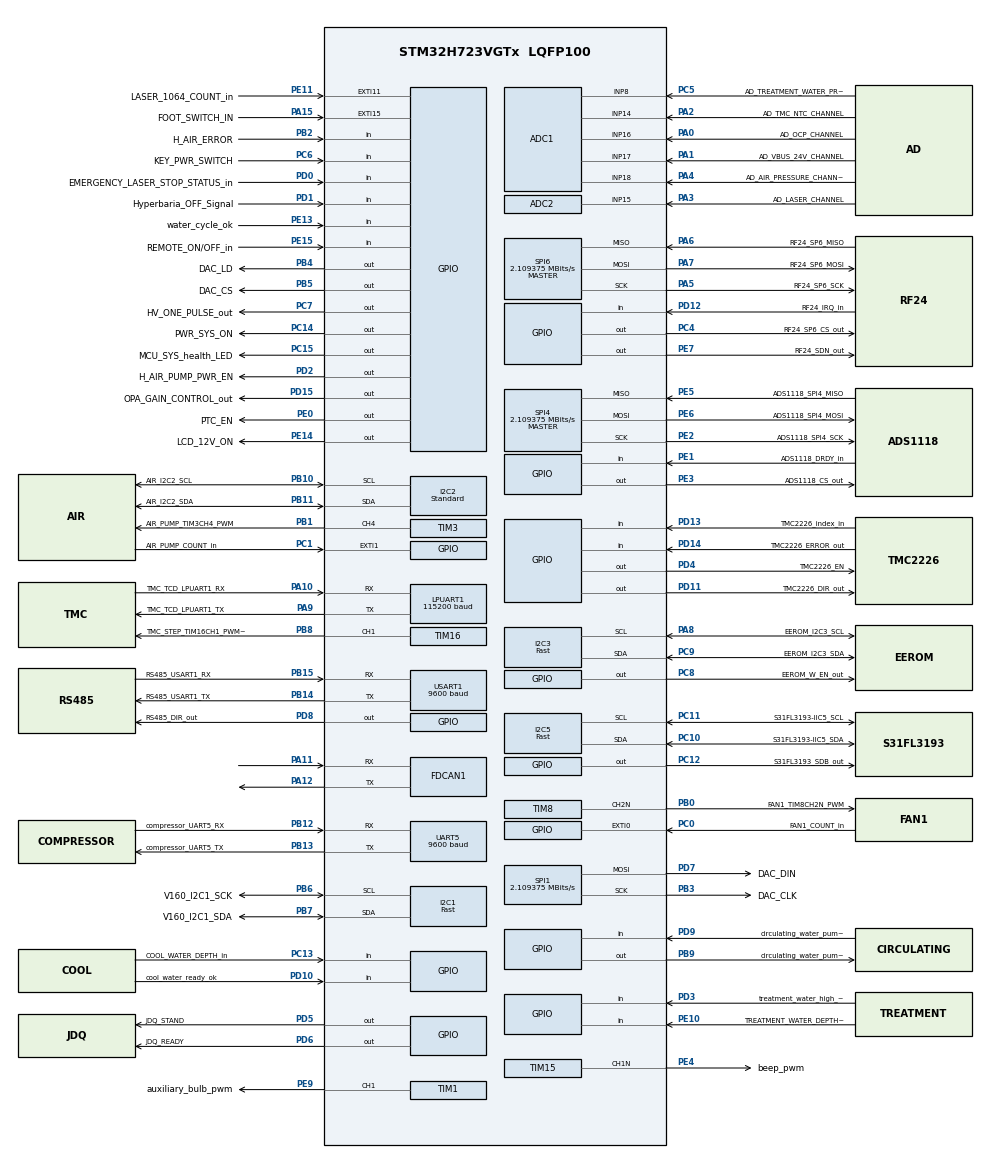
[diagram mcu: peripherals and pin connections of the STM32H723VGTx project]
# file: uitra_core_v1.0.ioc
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ADC1.Channel-11\#ChannelRegularConversion=ADC_CHANNEL_8
ADC1.Channel-12\#ChannelRegularConversion=ADC_CHANNEL_14
ADC1.Channel-13\#ChannelRegularConversion=ADC_CHANNEL_16
ADC1.Channel-14\#ChannelRegularConversion=ADC_CHANNEL_17
ADC1.Channel-16\#ChannelRegularConversion=ADC_CHANNEL_18
ADC1.ClockPrescalerADC3=ADC_CLOCK_ASYNC_DIV4
ADC1.ContinuousConvMode=DISABLE
ADC1.ConversionDataManagement=ADC_CONVERSIONDATA_DMA_CIRCULAR
ADC1.EOCSelection=ADC_EOC_SEQ_CONV
ADC1.EnableInjectedConversion=DISABLE
ADC1.ExternalTrigConv=ADC_EXTERNALTRIG_T6_TRGO
ADC1.LowPowerAutoWait=ENABLE
ADC1.NbrOfConversion=5
ADC1.NbrOfConversionFlag=1
ADC1.OffsetNumber-11\#ChannelRegularConversion=ADC_OFFSET_NONE
ADC1.OffsetNumber-12\#ChannelRegularConversion=ADC_OFFSET_NONE
ADC1.OffsetNumber-13\#ChannelRegularConversion=ADC_OFFSET_NONE
ADC1.OffsetNumber-14\#ChannelRegularConversion=ADC_OFFSET_NONE
ADC1.OffsetNumber-16\#ChannelRegularConversion=ADC_OFFSET_NONE
ADC1.OffsetSignedSaturation-11\#ChannelRegularConversion=DISABLE
ADC1.OffsetSignedSaturation-12\#ChannelRegularConversion=DISABLE
ADC1.OffsetSignedSaturation-13\#ChannelRegularConversion=DISABLE
ADC1.OffsetSignedSaturation-14\#ChannelRegularConversion=DISABLE
ADC1.OffsetSignedSaturation-16\#ChannelRegularConversion=DISABLE
ADC1.Rank-11\#ChannelRegularConversion=1
ADC1.Rank-12\#ChannelRegularConversion=2
ADC1.Rank-13\#ChannelRegularConversion=3
ADC1.Rank-14\#ChannelRegularConversion=4
ADC1.Rank-16\#ChannelRegularConversion=5
ADC1.SamplingTime-11\#ChannelRegularConversion=ADC_SAMPLETIME_64CYCLES_5
ADC1.SamplingTime-12\#ChannelRegularConversion=ADC_SAMPLETIME_64CYCLES_5
ADC1.SamplingTime-13\#ChannelRegularConversion=ADC_SAMPLETIME_64CYCLES_5
ADC1.SamplingTime-14\#ChannelRegularConversion=ADC_SAMPLETIME_64CYCLES_5
ADC1.SamplingTime-16\#ChannelRegularConversion=ADC_SAMPLETIME_64CYCLES_5
ADC1.master=1
ADC2.Channel-0\#ChannelRegularConversion=ADC_CHANNEL_15
ADC2.ClockPrescalerADC3=ADC_CLOCK_ASYNC_DIV4
ADC2.ContinuousConvMode=ENABLE
ADC2.ConversionDataManagement=ADC_CONVERSIONDATA_DMA_ONESHOT
ADC2.EOCSelection=ADC_EOC_SEQ_CONV
ADC2.EnableInjectedConversion=DISABLE
ADC2.EnableRegularConversion=ENABLE
ADC2.ExternalTrigConv=ADC_SOFTWARE_START
ADC2.LowPowerAutoWait=ENABLE
ADC2.NbrOfConversionFlag=1
ADC2.OffsetNumber-0\#ChannelRegularConversion=ADC_OFFSET_NONE
ADC2.OffsetSignedSaturation-0\#ChannelRegularConversion=DISABLE
ADC2.Rank-0\#ChannelRegularConversion=1
ADC2.SamplingTime-0\#ChannelRegularConversion=ADC_SAMPLETIME_64CYCLES_5
CORTEX_M7.CPU_DCache=Enabled
CORTEX_M7.CPU_ICache=Enabled
CORTEX_M7.Enable_S-Cortex_Memory_Protection_Unit_Region1_Settings_S=__NULL
CORTEX_M7.Enable_Spec=MPU_REGION_ENABLE
CORTEX_M7.default_mode_Activation=1
Dma.ADC1.0.Direction=DMA_PERIPH_TO_MEMORY
Dma.ADC1.0.EventEnable=DISABLE
Dma.ADC1.0.FIFOMode=DMA_FIFOMODE_ENABLE
Dma.ADC1.0.FIFOThreshold=DMA_FIFO_THRESHOLD_FULL
Dma.ADC1.0.Instance=DMA1_Stream0
Dma.ADC1.0.MemBurst=DMA_MBURST_SINGLE
Dma.ADC1.0.MemDataAlignment=DMA_MDATAALIGN_HALFWORD
Dma.ADC1.0.MemInc=DMA_MINC_ENABLE
Dma.ADC1.0.Mode=DMA_CIRCULAR
Dma.ADC1.0.PeriphBurst=DMA_PBURST_SINGLE
Dma.ADC1.0.PeriphDataAlignment=DMA_PDATAALIGN_HALFWORD
Dma.ADC1.0.PeriphInc=DMA_PINC_DISABLE
Dma.ADC1.0.Polarity=HAL_DMAMUX_REQ_GEN_RISING
Dma.ADC1.0.Priority=DMA_PRIORITY_LOW
Dma.ADC1.0.RequestNumber=1
Dma.ADC1.0.SignalID=NONE
Dma.ADC1.0.SyncEnable=DISABLE
Dma.ADC1.0.SyncPolarity=HAL_DMAMUX_SYNC_NO_EVENT
Dma.ADC1.0.SyncRequestNumber=1
Dma.ADC1.0.SyncSignalID=NONE
Dma.ADC2.1.Direction=DMA_PERIPH_TO_MEMORY
Dma.ADC2.1.EventEnable=DISABLE
Dma.ADC2.1.FIFOMode=DMA_FIFOMODE_ENABLE
Dma.ADC2.1.FIFOThreshold=DMA_FIFO_THRESHOLD_FULL
Dma.ADC2.1.Instance=DMA2_Stream0
Dma.ADC2.1.MemBurst=DMA_MBURST_SINGLE
Dma.ADC2.1.MemDataAlignment=DMA_MDATAALIGN_HALFWORD
Dma.ADC2.1.MemInc=DMA_MINC_ENABLE
Dma.ADC2.1.Mode=DMA_CIRCULAR
Dma.ADC2.1.PeriphBurst=DMA_PBURST_SINGLE
Dma.ADC2.1.PeriphDataAlignment=DMA_PDATAALIGN_HALFWORD
Dma.ADC2.1.PeriphInc=DMA_PINC_DISABLE
Dma.ADC2.1.Polarity=HAL_DMAMUX_REQ_GEN_RISING
Dma.ADC2.1.Priority=DMA_PRIORITY_LOW
Dma.ADC2.1.RequestNumber=1
Dma.ADC2.1.SignalID=NONE
Dma.ADC2.1.SyncEnable=DISABLE
Dma.ADC2.1.SyncPolarity=HAL_DMAMUX_SYNC_NO_EVENT
Dma.ADC2.1.SyncRequestNumber=1
Dma.ADC2.1.SyncSignalID=NONE
Dma.Request0=ADC1
Dma.Request1=ADC2
FDCAN1.AutoRetransmission=DISABLE
FDCAN1.CalculateBaudRateNominal=125000
FDCAN1.CalculateTimeBitNominal=8000
FDCAN1.CalculateTimeQuantumNominal=400.0
FDCAN1.ClockCalibrationCCU=DISABLE
FDCAN1.DataPrescaler=1
FDCAN1.NominalPrescaler=12
FDCAN1.NominalSyncJumpWidth=1
FDCAN1.NominalTimeSeg1=10
FDCAN1.NominalTimeSeg2=9
FDCAN1.RxBuffersNbr=64
FDCAN1.RxFifo0ElmtSize=FDCAN_DATA_BYTES_8
FDCAN1.RxFifo0ElmtsNbr=64
FDCAN1.RxFifo1ElmtsNbr=0
FDCAN1.StdFiltersNbr=0
FDCAN1.TxFifoQueueElmtsNbr=3
FDCAN1.TxFifoQueueMode=FDCAN_TX_FIFO_OPERATION
FREERTOS.BinarySemaphores01=powerOffBinarySem02,Dynamic,NULL,Depleted;laserPrapareReqSem03,Dynamic,NULL,Depleted;laserCloseSem05,Dynamic,NULL,Depleted;hmiCanBusIdleSem06,Dynamic,NULL,Depleted;jdqHeart100msBinarySem05,Dynamic,NULL,Depleted;aux1SHeartBinarySem06,Dynamic,NULL,Depleted
FREERTOS.Events01=auxStatusEvent01,Static,auxStatusEvent01ControlBlock;laserEvent02,Static,laserEvent02ControlBlock
FREERTOS.Queues01=rgbQueue02,3,uint16_t,0,Dynamic,NULL,NULL;musicQueue03,3,uint16_t,0,Dynamic,NULL,NULL;keyJTMessageQueue01,3,uint16_t,0,Dynamic,NULL,NULL;jdqGwb3200CtrMessageQueue04,3,8,1,Static,jdqGwb3200CtrMessageQueue04Buffer,jdqGwb3200CtrMessageQueue04ControlBlock
FREERTOS.Tasks01=defaultTask,40,312,StartDefaultTask,Default,NULL,Dynamic,NULL,NULL;myTask02,28,312,auxTask02,Default,NULL,Dynamic,NULL,NULL;myTask03,31,160,keyScanTask03,Default,NULL,Dynamic,NULL,NULL;myTask04,30,312,laserWorkTask04,Default,NULL,Dynamic,NULL,NULL;myTask05,29,256,fastAuxTask05,Default,NULL,Dynamic,NULL,NULL;myTask06,29,192,hmiAppTask06,Default,NULL,Dynamic,NULL,NULL;myTask07,29,256,canReceiveTask07,Default,NULL,Dynamic,NULL,NULL;myTask08,31,128,powerOffTask08,Default,NULL,Dynamic,NULL,NULL;myTask09,29,256,laserProhotTask09,Default,NULL,Dynamic,NULL,NULL;myTask10,28,256,ge2117ManageTask10,Default,NULL,Dynamic,NULL,NULL;myTask11,28,128,musicTask11,Default,NULL,Dynamic,NULL,NULL;jdqGWB3200wTask,29,256,jdqGWB3200wTask12,Default,NULL,Dynamic,NULL,NULL
FREERTOS.Timers01=laserWorkTimer01,LaserWorkTimerCallback01,osTimerOnce,Default,NULL,Dynamic,NULL;cleanTimer02,cleanWaterCallback02,osTimerOnce,Default,NULL,Dynamic,NULL;tmcMaxRunTimer03,tmcMaxRunTimesCallback03,osTimerOnce,Default,NULL,Dynamic,NULL;jdqHeart100msTimer04,jdqHeart100msCallback04,osTimerPeriodic,Default,NULL,Dynamic,NULL
FREERTOS.configTOTAL_HEAP_SIZE=32768
FREERTOS.configUSE_IDLE_HOOK=1
I2C1.CustomTiming=Disabled
I2C1.I2C_Fall_Time=50
I2C1.I2C_Rise_Time=50
I2C1.I2C_Speed_Mode=I2C_Fast
I2C1.Timing=0x10A02671
I2C2.CustomTiming=Disabled
I2C2.I2C_Fall_Time=50
I2C2.I2C_Rise_Time=100
I2C2.I2C_Speed_Mode=I2C_Standard
I2C2.Speed=100
I2C2.Timing=0x30B08DB9
I2C3.CustomTiming=Disabled
I2C3.I2C_Fall_Time=10
I2C3.I2C_Rise_Time=100
I2C3.I2C_Speed_Mode=I2C_Fast
I2C3.NoStretchMode=I2C_NOSTRETCH_DISABLE
I2C3.Timing=0x40500E2D
I2C5.I2C_Fall_Time=10
I2C5.I2C_Rise_Time=100
I2C5.I2C_Speed_Mode=I2C_Fast
I2C5.Timing=0x40500E2D
IWDG1.Prescaler=IWDG_PRESCALER_32
IWDG1.Reload=2000
IWDG1.Window=2000
LPUART1.BaudRate=115200
LPUART1.OneBitSampling=UART_ONE_BIT_SAMPLE_ENABLE
Mcu.Family=STM32H7
Mcu.Name=STM32H723VGTx
Mcu.Package=LQFP100
Mcu.UserConstants=adtest,adtest
NVIC.ADC_IRQn=true\:5\:0\:false\:false\:true\:true\:true\:true\:true
NVIC.DMA1_Stream0_IRQn=true\:5\:0\:false\:false\:true\:false\:false\:true\:true
NVIC.DMA2_Stream0_IRQn=true\:5\:0\:false\:false\:true\:false\:false\:true\:true
NVIC.EXTI0_IRQn=true\:5\:0\:false\:false\:true\:true\:true\:true\:true
NVIC.EXTI15_10_IRQn=true\:5\:0\:false\:false\:true\:true\:true\:true\:true
NVIC.EXTI1_IRQn=true\:5\:0\:false\:false\:true\:true\:true\:true\:true
NVIC.LPUART1_IRQn=true\:5\:0\:true\:false\:true\:true\:true\:true\:true
NVIC.PriorityGroup=NVIC_PRIORITYGROUP_4
NVIC.TIM17_IRQn=true\:5\:0\:false\:false\:true\:true\:true\:true\:true
NVIC.TIM23_IRQn=true\:5\:0\:false\:false\:true\:true\:true\:true\:true
NVIC.TIM2_IRQn=true\:5\:0\:false\:false\:true\:true\:true\:true\:true
NVIC.TIM6_DAC_IRQn=true\:15\:0\:false\:false\:true\:false\:false\:true\:true
NVIC.TIM7_IRQn=true\:5\:0\:false\:false\:true\:true\:true\:true\:true
NVIC.TimeBase=TIM6_DAC_IRQn
NVIC.TimeBaseIP=TIM6
NVIC.UART5_IRQn=true\:5\:0\:false\:false\:true\:true\:true\:true\:true
NVIC.USART1_IRQn=true\:5\:0\:false\:false\:true\:true\:true\:true\:true
PA0.GPIO_Label=AD_OCP_CHANNEL
PA0.Mode=IN16-Single-Ended
PA0.Signal=ADC1_INP16
PA1.GPIO_Label=AD_VBUS_24V_CHANNEL
PA1.Mode=IN17-Single-Ended
PA1.Signal=ADC1_INP17
PA10.GPIO_Label=TMC_TCD_LPUART1_RX
PA10.Mode=Asynchronous
PA10.Signal=LPUART1_RX
PA11.Mode=FDCAN_Activate
PA11.Signal=FDCAN1_RX
PA12.Mode=FDCAN_Activate
PA12.Signal=FDCAN1_TX
PA13(JTMS/SWDIO).Mode=Serial_Wire
PA13(JTMS/SWDIO).Signal=DEBUG_JTMS-SWDIO
PA14(JTCK/SWCLK).Mode=Serial_Wire
PA14(JTCK/SWCLK).Signal=DEBUG_JTCK-SWCLK
PA15(JTDI).GPIO_Label=FOOT_SWITCH_IN
PA15(JTDI).GPIO_ModeDefaultEXTI=GPIO_MODE_IT_RISING
PA15(JTDI).Signal=GPXTI15
PA2.GPIO_Label=AD_TMC_NTC_CHANNEL
PA2.Signal=ADCx_INP14
PA3.GPIO_Label=AD_LASER_CHANNEL
PA3.Signal=ADCx_INP15
PA4.GPIO_Label=AD_AIR_PRESSURE_CHANNEL
PA4.Signal=ADCx_INP18
PA5.GPIO_Label=RF24_SP6_SCK
PA5.GPIO_PuPd=GPIO_NOPULL
PA5.Mode=Full_Duplex_Master
PA5.Signal=SPI6_SCK
PA6.GPIO_Label=RF24_SP6_MISO
PA6.GPIO_PuPd=GPIO_NOPULL
PA6.Mode=Full_Duplex_Master
PA6.Signal=SPI6_MISO
PA7.GPIO_Label=RF24_SP6_MOSI
PA7.GPIO_PuPd=GPIO_NOPULL
PA7.Mode=Full_Duplex_Master
PA7.Signal=SPI6_MOSI
PA8.GPIO_Label=EEROM_I2C3_SCL
PA8.Mode=I2C
PA8.Signal=I2C3_SCL
PA9.GPIO_Label=TMC_TCD_LPUART1_TX
PA9.Mode=Asynchronous
PA9.Signal=LPUART1_TX
PB0.GPIO_Label=FAN1_TIM8CH2N_PWM
PB0.Mode=PWM Generation2 CH2N
PB0.Signal=TIM8_CH2N
PB1.GPIO_Label=AIR_PUMP_TIM3CH4_PWM
PB1.Signal=S_TIM3_CH4
PB10.GPIO_Label=AIR_I2C2_SCL
PB10.Mode=I2C
PB10.Signal=I2C2_SCL
PB11.GPIO_Label=AIR_I2C2_SDA
PB11.Mode=I2C
PB11.Signal=I2C2_SDA
PB12.GPIO_Label=compressor_UART5_RX
PB12.Mode=Asynchronous
PB12.Signal=UART5_RX
PB13.GPIO_Label=compressor_UART5_TX
PB13.Mode=Asynchronous
PB13.Signal=UART5_TX
PB14.GPIO_Label=RS485_USART1_TX
PB14.Mode=Asynchronous
PB14.Signal=USART1_TX
PB15.GPIO_Label=RS485_USART1_RX
PB15.Mode=Asynchronous
PB15.Signal=USART1_RX
PB2.GPIO_Label=H_AIR_ERROR
PB2.Signal=GPIO_Input
PB3(JTDO/TRACESWO).GPIO_Label=DAC_CLK
PB3(JTDO/TRACESWO).Mode=TX_Only_Simplex_Unidirect_Master
PB3(JTDO/TRACESWO).Signal=SPI1_SCK
PB4(NJTRST).GPIO_Label=DAC_LD
PB4(NJTRST).Signal=GPIO_Output
PB5.GPIO_Label=DAC_CS
PB5.Signal=GPIO_Output
PB6.GPIO_Label=V160_I2C1_SCK
PB6.Mode=I2C
PB6.Signal=I2C1_SCL
PB7.GPIO_Label=V160_I2C1_SDA
PB7.Mode=I2C
PB7.Signal=I2C1_SDA
PB8.GPIO_Label=TMC_STEP_TIM16CH1_PWM_out
PB8.Signal=S_TIM16_CH1
PB9.GPIO_Label=circulating_water_pump_EN
PB9.Signal=GPIO_Output
PC0.GPIO_Label=FAN1_COUNT_in
PC0.GPIO_ModeDefaultEXTI=GPIO_MODE_IT_RISING
PC0.Signal=GPXTI0
PC1.GPIO_Label=AIR_PUMP_COUNT_in
PC1.GPIO_ModeDefaultEXTI=GPIO_MODE_IT_RISING
PC1.Signal=GPXTI1
PC10.GPIO_Label=S31FL3193-IIC5_SDA
PC10.Mode=I2C
PC10.Signal=I2C5_SDA
PC11.GPIO_Label=S31FL3193-IIC5_SCL
PC11.Mode=I2C
PC11.Signal=I2C5_SCL
PC12.GPIO_Label=S31FL3193_SDB_out
PC12.PinState=GPIO_PIN_SET
PC12.Signal=GPIO_Output
PC13.GPIO_Label=COOL_WATER_DEPTH_in
PC13.Signal=GPIO_Input
PC14-OSC32_IN.GPIO_Label=PWR_SYS_ON
PC14-OSC32_IN.GPIO_ModeDefaultOutputPP=GPIO_MODE_OUTPUT_PP
PC14-OSC32_IN.GPIO_PuPd=GPIO_NOPULL
PC14-OSC32_IN.PinState=GPIO_PIN_SET
PC14-OSC32_IN.Signal=GPIO_Output
PC15-OSC32_OUT.GPIO_Label=MCU_SYS_health_LED
PC15-OSC32_OUT.Signal=GPIO_Output
PC4.GPIO_Label=RF24_SP6_CS_out
PC4.Signal=GPIO_Output
PC5.GPIO_Label=AD_TREATMENT_WATER_PRESSURE_CHANNEL
PC5.Signal=ADCx_INP8
PC6.GPIO_Label=KEY_PWR_SWITCH
PC6.Signal=GPIO_Input
PC7.GPIO_Label=HV_ONE_PULSE_out
PC7.Signal=GPIO_Output
PC8.GPIO_Label=EEROM_W_EN_out
PC8.PinState=GPIO_PIN_SET
PC8.Signal=GPIO_Output
PC9.GPIO_Label=EEROM_I2C3_SDA
PC9.Mode=I2C
PC9.Signal=I2C3_SDA
PD0.GPIO_Label=EMERGENCY_LASER_STOP_STATUS_in
PD0.Signal=GPIO_Input
PD1.GPIO_Label=Hyperbaria_OFF_Signal
PD1.Signal=GPIO_Input
PD10.GPIO_Label=cool_water_ready_ok
PD10.Signal=GPIO_Input
PD11.GPIO_Label=TMC2226_DIR_out
PD11.Signal=GPIO_Output
PD12.GPIO_Label=RF24_IRQ_in
PD12.Signal=GPIO_Input
PD13.GPIO_Label=TMC2226_index_in
PD13.Signal=GPIO_Input
PD14.GPIO_Label=TMC2226_ERROR_out
PD14.Signal=GPIO_Input
PD15.GPIO_Label=OPA_GAIN_CONTROL_out
PD15.Signal=GPIO_Output
PD2.GPIO_Label=H_AIR_PUMP_PWR_EN
PD2.PinState=GPIO_PIN_SET
PD2.Signal=GPIO_Output
PD3.GPIO_Label=treatment_water_high_pressure_off_status_in
PD3.Signal=GPIO_Input
PD4.GPIO_Label=TMC2226_EN
PD4.PinState=GPIO_PIN_SET
PD4.Signal=GPIO_Output
PD5.GPIO_Label=JDQ_STAND
PD5.Signal=GPIO_Output
PD6.GPIO_Label=JDQ_READY
PD6.Signal=GPIO_Output
PD7.GPIO_Label=DAC_DIN
PD7.Mode=TX_Only_Simplex_Unidirect_Master
PD7.Signal=SPI1_MOSI
PD8.GPIO_Label=RS485_DIR_out
PD8.Signal=GPIO_Output
PD9.GPIO_Label=circulating_water_pump_status_in
PD9.Signal=GPIO_Input
PE0.GPIO_Label=PTC_EN
PE0.PinState=GPIO_PIN_RESET
PE0.Signal=GPIO_Output
PE1.GPIO_Label=ADS1118_DRDY_in
PE1.Signal=GPIO_Input
PE10.GPIO_Label=TREATMENT_WATER_DEPTH_in
PE10.Signal=GPIO_Input
PE11.GPIO_Label=LASER_1064_COUNT_in
PE11.GPIO_ModeDefaultEXTI=GPIO_MODE_IT_RISING
PE11.Signal=GPXTI11
PE13.GPIO_Label=water_cycle_ok
PE13.Signal=GPIO_Input
PE14.GPIO_Label=LCD_12V_ON
PE14.PinState=GPIO_PIN_SET
PE14.Signal=GPIO_Output
PE15.GPIO_Label=REMOTE_ON/OFF_in
PE15.Signal=GPIO_Input
PE2.GPIO_Label=ADS1118_SPI4_SCK
PE2.Mode=Full_Duplex_Master
PE2.Signal=SPI4_SCK
PE3.GPIO_Label=ADS1118_CS_out
PE3.Signal=GPIO_Output
PE4.GPIO_Label=beep_pwm
PE4.Mode=PWM Generation1 CH1N
PE4.Signal=TIM15_CH1N
PE5.GPIO_Label=ADS1118_SPI4_MISO
PE5.Mode=Full_Duplex_Master
PE5.Signal=SPI4_MISO
PE6.GPIO_Label=ADS1118_SPI4_MOSI
PE6.Mode=Full_Duplex_Master
PE6.Signal=SPI4_MOSI
PE7.GPIO_Label=RF24_SDN_out
PE7.Signal=GPIO_Output
PE9.GPIO_Label=auxiliary_bulb_pwm
PE9.Signal=S_TIM1_CH1
PH0-OSC_IN.Mode=HSE-External-Oscillator
PH0-OSC_IN.Signal=RCC_OSC_IN
PH1-OSC_OUT.Mode=HSE-External-Oscillator
PH1-OSC_OUT.Signal=RCC_OSC_OUT
ProjectManager.HeapSize=0x800
ProjectManager.StackSize=0x400
ProjectManager.TargetToolchain=MDK-ARM V5.32
RCC.ADCFreq_Value=135000000
RCC.APB1Freq_Value=135000000
RCC.APB2Freq_Value=135000000
RCC.APB3Freq_Value=135000000
RCC.APB4Freq_Value=135000000
RCC.CortexFreq_Value=67500000
RCC.Cortex_Div=SYSTICK_CLKSOURCE_HCLK_DIV8
RCC.D1PPRE=RCC_APB3_DIV2
RCC.D2PPRE1=RCC_APB1_DIV2
RCC.D2PPRE2=RCC_APB2_DIV2
RCC.D3PPRE=RCC_APB4_DIV2
RCC.DIVM1=2
RCC.DIVM2=2
RCC.DIVM3=4
RCC.DIVN1=45
RCC.DIVN2=45
RCC.DIVN3=45
RCC.DIVP1=1
RCC.DIVP2=4
RCC.DIVQ1=4
RCC.DIVQ2=18
RCC.DIVR1=4
RCC.FDCANCLockSelection=RCC_FDCANCLKSOURCE_PLL2
RCC.HCLKFreq_Value=270000000
RCC.HPRE=RCC_HCLK_DIV2
RCC.HSE_Timout=2000
RCC.HSE_VALUE=24000000
RCC.PLL1_VCI_Range-AdvancedSettings=RCC_PLL1VCIRANGE_0
RCC.PLL1_VCO_SEL-AdvancedSettings=RCC_PLL1VCOMEDIUM
RCC.PLL2FRACN=0
RCC.PLL2_VCI_Range-AdvancedSettings=RCC_PLL2VCIRANGE_0
RCC.PLL2_VCO_SEL-AdvancedSettings=RCC_PLL2VCOMEDIUM
RCC.PLL3_VCI_Range-AdvancedSettings=RCC_PLL3VCIRANGE_0
RCC.PLL3_VCO_SEL-AdvancedSettings=RCC_PLL3VCOMEDIUM
RCC.PLLFRACN=0
RCC.PLLSourceVirtual=RCC_PLLSOURCE_HSE
RCC.SPI6CLockSelection=RCC_SPI6CLKSOURCE_PLL3
RCC.SYSCLKFreq_VALUE=540000000
RCC.SYSCLKSource=RCC_SYSCLKSOURCE_PLLCLK
RCC.SupplySource=PWR_LDO_SUPPLY
RCC.USBFreq_Value=135000000
SH.ADCx_INP14.0=ADC1_INP14,IN14-Single-Ended
SH.ADCx_INP15.0=ADC2_INP15,IN15-Single-Ended
SH.ADCx_INP18.0=ADC1_INP18,IN18-Single-Ended
SH.ADCx_INP8.0=ADC1_INP8,IN8-Single-Ended
SH.S_TIM16_CH1.0=TIM16_CH1,PWM Generation1 CH1
SH.S_TIM1_CH1.0=TIM1_CH1,PWM Generation1 CH1
SH.S_TIM3_CH4.0=TIM3_CH4,PWM Generation4 CH4
SPI1.BaudRatePrescaler=SPI_BAUDRATEPRESCALER_64
SPI1.CalculateBaudRate=2.109375 MBits/s
SPI1.DataSize=SPI_DATASIZE_8BIT
SPI1.Direction=SPI_DIRECTION_2LINES_TXONLY
SPI1.Mode=SPI_MODE_MASTER
SPI1.NSSPMode=SPI_NSS_PULSE_DISABLE
SPI1.VirtualType=VM_MASTER
SPI4.BaudRatePrescaler=SPI_BAUDRATEPRESCALER_64
SPI4.CLKPhase=SPI_PHASE_2EDGE
SPI4.CLKPolarity=SPI_POLARITY_HIGH
SPI4.CalculateBaudRate=2.109375 MBits/s
SPI4.DataSize=SPI_DATASIZE_8BIT
SPI4.Direction=SPI_DIRECTION_2LINES
SPI4.FirstBit=SPI_FIRSTBIT_MSB
SPI4.MasterInterDataIdleness=SPI_MASTER_INTERDATA_IDLENESS_00CYCLE
SPI4.MasterSSIdleness=SPI_MASTER_SS_IDLENESS_00CYCLE
SPI4.Mode=SPI_MODE_MASTER
SPI4.VirtualType=VM_MASTER
SPI6.BaudRatePrescaler=SPI_BAUDRATEPRESCALER_64
SPI6.CLKPhase=SPI_PHASE_1EDGE
SPI6.CLKPolarity=SPI_POLARITY_LOW
SPI6.CalculateBaudRate=2.109375 MBits/s
SPI6.DataSize=SPI_DATASIZE_8BIT
SPI6.Direction=SPI_DIRECTION_2LINES
SPI6.FifoThreshold=SPI_FIFO_THRESHOLD_01DATA
SPI6.MasterInterDataIdleness=SPI_MASTER_INTERDATA_IDLENESS_00CYCLE
SPI6.MasterSSIdleness=SPI_MASTER_SS_IDLENESS_00CYCLE
SPI6.Mode=SPI_MODE_MASTER
SPI6.VirtualType=VM_MASTER
TIM1.AutoReloadPreload=TIM_AUTORELOAD_PRELOAD_ENABLE
TIM1.Channel-PWM\ Generation1\ CH1=TIM_CHANNEL_1
TIM1.Period=999
TIM1.Prescaler=53
TIM1.Pulse-PWM\ Generation1\ CH1=499
TIM15.AutoReloadPreload=TIM_AUTORELOAD_PRELOAD_ENABLE
TIM15.Channel-PWM\ Generation1\ CH1N=TIM_CHANNEL_1
TIM15.OCNIdleState_1=TIM_OCNIDLESTATE_RESET
TIM15.OCNPolarity_1=TIM_OCNPOLARITY_HIGH
TIM15.Period=999
TIM15.Prescaler=269
TIM15.Pulse-PWM\ Generation1\ CH1N=499
TIM16.AutoReloadPreload=TIM_AUTORELOAD_PRELOAD_ENABLE
TIM16.Channel=TIM_CHANNEL_1
TIM16.ClockDivision=TIM_CLOCKDIVISION_DIV1
TIM16.Period=999
TIM16.Prescaler=269
TIM16.Pulse=499
TIM17.AutoReloadPreload=TIM_AUTORELOAD_PRELOAD_DISABLE
TIM17.Period=29
TIM17.Prescaler=269
TIM2.AutoReloadPreload=TIM_AUTORELOAD_PRELOAD_ENABLE
TIM2.Channel-Output\ Compare2\ No\ Output=TIM_CHANNEL_2
TIM2.CounterMode=TIM_COUNTERMODE_DOWN
TIM2.OC2Preload=ENABLE
TIM2.OCPolarity_2=TIM_OCPOLARITY_LOW
TIM2.Period=4999
TIM2.Prescaler=26
TIM2.Pulse-Output\ Compare2\ No\ Output=300
TIM2.TIM_MasterOutputTrigger=TIM_TRGO_RESET
TIM2.TIM_MasterSlaveMode=TIM_MASTERSLAVEMODE_DISABLE
TIM23.AutoReloadPreload=TIM_AUTORELOAD_PRELOAD_ENABLE
TIM23.Period=99999
TIM23.Prescaler=2699
TIM3.AutoReloadPreload=TIM_AUTORELOAD_PRELOAD_ENABLE
TIM3.Channel-PWM\ Generation4\ CH4=TIM_CHANNEL_4
TIM3.Period=124
TIM3.Prescaler=53
TIM7.AutoReloadPreload=TIM_AUTORELOAD_PRELOAD_ENABLE
TIM7.Period=1000
TIM7.Prescaler=269
TIM8.AutoReloadPreload=TIM_AUTORELOAD_PRELOAD_ENABLE
TIM8.Channel-PWM\ Generation2\ CH2N=TIM_CHANNEL_2
TIM8.OCNIdleState_2=TIM_OCNIDLESTATE_RESET
TIM8.Period=399
TIM8.Prescaler=26
TIM8.Pulse-PWM\ Generation2\ CH2N=199
UART5.BaudRate=9600
USART1.BaudRate=9600
USART1.VirtualMode-Asynchronous=VM_ASYNC
VP_FREERTOS_VS_CMSIS_V2.Mode=CMSIS_V2
VP_IWDG1_VS_IWDG.Mode=IWDG_Activate
VP_MEMORYMAP_VS_MEMORYMAP.Mode=CurAppReg
VP_PWR_V_PVD_IN.Mode=Mode_PVD_Int
VP_SYS_VS_tim6.Mode=TIM6
VP_TIM16_VS_ClockSourceINT.Mode=Enable_Timer
VP_TIM17_VS_ClockSourceINT.Mode=Enable_Timer
VP_TIM23_VS_ClockSourceINT.Mode=Internal
VP_TIM2_VS_ClockSourceINT.Mode=Internal
VP_TIM2_VS_no_output2.Mode=Output Compare2 No Output
VP_TIM7_VS_ClockSourceINT.Mode=Enable_Timer
VP_VREFBUF_V_VREFBUF.Mode=ExternalMode
board=custom

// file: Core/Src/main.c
/* USER CODE BEGIN Header */
/**
  ******************************************************************************
  * @file           : main.c
  * @brief          : Main program body
  ******************************************************************************
  * @attention
  *
  * Copyright (c) 2025 STMicroelectronics.
  * All rights reserved.
  *
  * This software is licensed under terms that can be found in the LICENSE file
  * in the root directory of this software component.
  * If no LICENSE file comes with this software, it is provided AS-IS.
  *
  ******************************************************************************
  */
/* USER CODE END Header */
#include "main.h"
#include "cmsis_os.h"
#include "adc.h"
#include "dma.h"
#include "fdcan.h"
#include "i2c.h"
#include "iwdg.h"
#include "usart.h"
#include "memorymap.h"
#include "spi.h"
#include "tim.h"
#include "gpio.h"

/* USER CODE BEGIN Includes */
#include <stdio.h>
#include <stdbool.h>
#include <string.h>
#include "one_wire_bus.h"
#include "tmc2226_step_bsp.h"
#include "fan_bsp.h"
/* USER CODE END Includes */

void SystemClock_Config(void);
void PeriphCommonClock_Config(void);
static void MPU_Config(void);
void MX_FREERTOS_Init(void);

int main(void)
{

  /* MPU Configuration--------------------------------------------------------*/
  MPU_Config();

  /* Enable the CPU Cache */

  /* Enable I-Cache---------------------------------------------------------*/
  SCB_EnableICache();

  /* Enable D-Cache---------------------------------------------------------*/
  SCB_EnableDCache();

  /* MCU Configuration--------------------------------------------------------*/

  /* Reset of all peripherals, Initializes the Flash interface and the Systick. */
  HAL_Init();

  /* USER CODE BEGIN Init */

  //SCB->CACR|=1<<2;//DCATCH
  /* USER CODE END Init */

  /* Configure the system clock */
  SystemClock_Config();

  /* Configure the peripherals common clocks */
  PeriphCommonClock_Config();

  /* Initialize all configured peripherals */
  MX_GPIO_Init();
  MX_DMA_Init();
  MX_FDCAN1_Init();
  MX_I2C1_Init();
  MX_I2C2_Init();
  MX_I2C3_Init();
  MX_I2C5_Init();
  MX_LPUART1_UART_Init();
  MX_UART5_Init();
  MX_USART1_UART_Init();
  MX_SPI4_Init();
  MX_SPI6_Init();
  MX_TIM1_Init();
  MX_TIM3_Init();
  MX_ADC1_Init();
  MX_TIM16_Init();
  //MX_IWDG1_Init();
  MX_ADC2_Init();
  MX_TIM8_Init();
  MX_SPI1_Init();
  MX_TIM17_Init();
  MX_TIM15_Init();
  MX_TIM2_Init();
  MX_TIM7_Init();
  MX_TIM23_Init();
  /* USER CODE BEGIN 2 */
  DWT_Init();
  char verBuff[19]={0};
  memcpy(verBuff,__TIME__,8);
  memcpy(&verBuff[8],__DATE__,11);
  if(verBuff[12]<'1') verBuff[12]='0';
  #ifdef DEBUG_MSG_UART
  DEBUG_PRINTF("uitra_V1.0.%c%c%c%c%c%c%c%c%c%c%c%c --DATE=%s\r\n",verBuff[0],verBuff[1],verBuff[3],verBuff[4],verBuff[6],verBuff[7],verBuff[12],verBuff[13],verBuff[15],verBuff[16],verBuff[17],verBuff[18],__DATE__);
  #else
  printf("uitra_V1.0.%c%c%c%c%c%c%c%c%c%c%c%c --DATE=%s\r\n",verBuff[0],verBuff[1],verBuff[3],verBuff[4],verBuff[6],verBuff[7],verBuff[12],verBuff[13],verBuff[15],verBuff[16],verBuff[17],verBuff[18],__DATE__);
  #endif
  /* USER CODE END 2 */

  /* Init scheduler */
  osKernelInitialize();

  /* Call init function for freertos objects (in cmsis_os2.c) */
  MX_FREERTOS_Init();

  /* Start scheduler */
  osKernelStart();

  /* We should never get here as control is now taken by the scheduler */

  /* Infinite loop */
  /* USER CODE BEGIN WHILE */
  while (1)
  {
    app_mcu_power_switch(DISABLE);//error close
    /* USER CODE END WHILE */

  }
}

void SystemClock_Config(void)
{
  RCC_OscInitTypeDef RCC_OscInitStruct = {0};
  RCC_ClkInitTypeDef RCC_ClkInitStruct = {0};

  /** Supply configuration update enable
  */
  HAL_PWREx_ConfigSupply(PWR_LDO_SUPPLY);

  /** Configure the main internal regulator output voltage
  */
  __HAL_PWR_VOLTAGESCALING_CONFIG(PWR_REGULATOR_VOLTAGE_SCALE0);

  while(!__HAL_PWR_GET_FLAG(PWR_FLAG_VOSRDY)) {}

  /** Initializes the RCC Oscillators according to the specified parameters
  * in the RCC_OscInitTypeDef structure.
  */
  RCC_OscInitStruct.OscillatorType = RCC_OSCILLATORTYPE_LSI|RCC_OSCILLATORTYPE_HSE;
  RCC_OscInitStruct.HSEState = RCC_HSE_ON;
  RCC_OscInitStruct.LSIState = RCC_LSI_ON;
  RCC_OscInitStruct.PLL.PLLState = RCC_PLL_ON;
  RCC_OscInitStruct.PLL.PLLSource = RCC_PLLSOURCE_HSE;
  RCC_OscInitStruct.PLL.PLLM = 2;
  RCC_OscInitStruct.PLL.PLLN = 45;
  RCC_OscInitStruct.PLL.PLLP = 1;
  RCC_OscInitStruct.PLL.PLLQ = 4;
  RCC_OscInitStruct.PLL.PLLR = 4;
  RCC_OscInitStruct.PLL.PLLRGE = RCC_PLL1VCIRANGE_3;
  RCC_OscInitStruct.PLL.PLLVCOSEL = RCC_PLL1VCOWIDE;
  RCC_OscInitStruct.PLL.PLLFRACN = 0;
  if (HAL_RCC_OscConfig(&RCC_OscInitStruct) != HAL_OK)
  {
    Error_Handler();
  }

  /** Initializes the CPU, AHB and APB buses clocks
  */
  RCC_ClkInitStruct.ClockType = RCC_CLOCKTYPE_HCLK|RCC_CLOCKTYPE_SYSCLK
                              |RCC_CLOCKTYPE_PCLK1|RCC_CLOCKTYPE_PCLK2
                              |RCC_CLOCKTYPE_D3PCLK1|RCC_CLOCKTYPE_D1PCLK1;
  RCC_ClkInitStruct.SYSCLKSource = RCC_SYSCLKSOURCE_PLLCLK;
  RCC_ClkInitStruct.SYSCLKDivider = RCC_SYSCLK_DIV1;
  RCC_ClkInitStruct.AHBCLKDivider = RCC_HCLK_DIV2;
  RCC_ClkInitStruct.APB3CLKDivider = RCC_APB3_DIV2;
  RCC_ClkInitStruct.APB1CLKDivider = RCC_APB1_DIV2;
  RCC_ClkInitStruct.APB2CLKDivider = RCC_APB2_DIV2;
  RCC_ClkInitStruct.APB4CLKDivider = RCC_APB4_DIV2;

  if (HAL_RCC_ClockConfig(&RCC_ClkInitStruct, FLASH_LATENCY_3) != HAL_OK)
  {
    Error_Handler();
  }
}

void PeriphCommonClock_Config(void)
{
  RCC_PeriphCLKInitTypeDef PeriphClkInitStruct = {0};

  /** Initializes the peripherals clock
  */
  PeriphClkInitStruct.PeriphClockSelection = RCC_PERIPHCLK_ADC|RCC_PERIPHCLK_FDCAN;
  PeriphClkInitStruct.PLL2.PLL2M = 2;
  PeriphClkInitStruct.PLL2.PLL2N = 45;
  PeriphClkInitStruct.PLL2.PLL2P = 4;
  PeriphClkInitStruct.PLL2.PLL2Q = 18;
  PeriphClkInitStruct.PLL2.PLL2R = 2;
  PeriphClkInitStruct.PLL2.PLL2RGE = RCC_PLL2VCIRANGE_3;
  PeriphClkInitStruct.PLL2.PLL2VCOSEL = RCC_PLL2VCOWIDE;
  PeriphClkInitStruct.PLL2.PLL2FRACN = 0;
  PeriphClkInitStruct.FdcanClockSelection = RCC_FDCANCLKSOURCE_PLL2;
  PeriphClkInitStruct.AdcClockSelection = RCC_ADCCLKSOURCE_PLL2;
  if (HAL_RCCEx_PeriphCLKConfig(&PeriphClkInitStruct) != HAL_OK)
  {
    Error_Handler();
  }
}

 /* MPU Configuration */

void MPU_Config(void)
{
  MPU_Region_InitTypeDef MPU_InitStruct = {0};

  /* Disables the MPU */
  HAL_MPU_Disable();

  /** Initializes and configures the Region and the memory to be protected
  */
  MPU_InitStruct.Enable = MPU_REGION_ENABLE;
  MPU_InitStruct.Number = MPU_REGION_NUMBER0;
  MPU_InitStruct.BaseAddress = 0x0;
  MPU_InitStruct.Size = MPU_REGION_SIZE_4GB;
  MPU_InitStruct.SubRegionDisable = 0x87;
  MPU_InitStruct.TypeExtField = MPU_TEX_LEVEL0;
  MPU_InitStruct.AccessPermission = MPU_REGION_NO_ACCESS;
  MPU_InitStruct.DisableExec = MPU_INSTRUCTION_ACCESS_DISABLE;
  MPU_InitStruct.IsShareable = MPU_ACCESS_SHAREABLE;
  MPU_InitStruct.IsCacheable = MPU_ACCESS_NOT_CACHEABLE;
  MPU_InitStruct.IsBufferable = MPU_ACCESS_NOT_BUFFERABLE;

  HAL_MPU_ConfigRegion(&MPU_InitStruct);
  /* Enables the MPU */
  HAL_MPU_Enable(MPU_PRIVILEGED_DEFAULT);

}

void HAL_TIM_PeriodElapsedCallback(TIM_HandleTypeDef *htim)
{
  if (htim->Instance == TIM6) {
    HAL_IncTick();
  }
  /* USER CODE BEGIN Callback 1 */
  if(htim->Instance == TIM17) {
     owb_tim_callback(30);
  }
  if(htim->Instance == TIM2)
  {
   // u_sys_param.sys_config_param.laser_pulse_count++;
    HAL_GPIO_WritePin(HV_ONE_PULSE_out_GPIO_Port, HV_ONE_PULSE_out_Pin, GPIO_PIN_RESET);
  }
  if(htim->Instance == TIM23)
  {
    cacul_fan_freq(1000);
    app_steps_pulse(CONTINUOUS_STEPS_COUNT);
  }
  /* USER CODE END Callback 1 */
}

void Error_Handler(void)
{
  /* USER CODE BEGIN Error_Handler_Debug */
  /* User can add his own implementation to report the HAL error return state */

  __disable_irq();
  //NVIC_SystemReset();
  while (1)
  {
  }
  /* USER CODE END Error_Handler_Debug */
}

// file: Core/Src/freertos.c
/* USER CODE BEGIN Header */
/**
  ******************************************************************************
  * File Name          : freertos.c
  * Description        : Code for freertos applications
  ******************************************************************************
  * @attention
  *
  * Copyright (c) 2025 STMicroelectronics.
  * All rights reserved.
  *
  * This software is licensed under terms that can be found in the LICENSE file
  * in the root directory of this software component.
  * If no LICENSE file comes with this software, it is provided AS-IS.
  *
  ******************************************************************************
  */
/* USER CODE END Header */

#include "FreeRTOS.h"
#include "task.h"
#include "main.h"
#include "cmsis_os.h"

/* USER CODE BEGIN Includes */
#include "stdlib.h"
#include <math.h>
#include "string.h"
#include "adc.h"
#include "gpio.h"
#include "tim.h"
#include "spi.h"
#include "fdcan.h"
#include "iwdg.h"
#include "air_gzp6816d_bsp.h"
#include "eeprom_bsp.h"
#include "max31865atp_bsp.h"
#include "IS31FL3193_bsp.h"
#include "tmc2226_step_bsp.h"
#include "mer_mcp1081_bsp.h"
#include "ge2117_gp_bsp.h"
#include  "jdq_bsp.h"
#include "drv_RF24L01.h"
#include "user_can1.h"
#include "fan_bsp.h"
#include "buzz_bsp.h"
#ifdef ONE_WIRE_BUS_JT_SLAVE
#include "one_wire_bus.h"
#endif

/* USER CODE END Includes */

typedef StaticQueue_t osStaticMessageQDef_t;
typedef StaticEventGroup_t osStaticEventGroupDef_t;
/* USER CODE BEGIN PTD */
sys_genaration_status sGenSta;
sys_enviroment_assistant_param sEnvParam;
LASER_CONTROL_PARAM laser_ctr_param;
U_SYS_CONFIG_PARAM u_sys_param;
U_SYS_CONFIG_PARAM u_sys_default_param;
/* USER CODE END PTD */

/* USER CODE BEGIN PD */

//auxStatusEvent01
#define EVENTS_AUX_STATUS_IO1_BIT  0x01
#define EVENTS_AUX_STATUS_IO2_BIT  0x01<<1
#define EVENTS_AUX_STATUS_IO3_BIT  0x01<<2
#define EVENTS_AUX_STATUS_IO4_BIT  0x01<<3
#define EVENTS_AUX_STATUS_IO5_BIT  0x01<<4
#define EVENTS_AUX_STATUS_IO6_BIT  0x01<<5
#define EVENTS_AUX_STATUS_IO7_BIT  0x01<<6//治疗水流动ok
#define EVENTS_AUX_STATUS_IO8_BIT  0x01<<7
#define EVENTS_AUX_STATUS_9_NTC_BIT                         0x0001<<8
#define EVENTS_AUX_STATUS_10_IBUS_BIT                       0x0001<<9
#define EVENTS_AUX_STATUS_11_VBUS_BIT                       0x0001<<10
#define EVENTS_AUX_STATUS_12_K1_TEMPRATURE_BIT           		0x0001<<11
#define EVENTS_AUX_STATUS_13_K2_TEMPRATURE_BIT           		0x0001<<12//激光器温度
#define EVENTS_AUX_STATUS_14_EMERGENCY_KEY_BIT              0x0001<<13
#define EVENTS_AUX_STATUS_15_TREATMEAT_WATER_DEPTH_BIT      0x0001<<14//治疗水位
#define EVENTS_AUX_STATUS_16_COOL_WATER_BIT                 0x0001<<15//冷却液位正常

#define EVENTS_AUX_STATUS_ALL_BITS     (EVENTS_AUX_STATUS_IO1_BIT|EVENTS_AUX_STATUS_IO2_BIT|EVENTS_AUX_STATUS_IO3_BIT|EVENTS_AUX_STATUS_IO4_BIT|EVENTS_AUX_STATUS_IO5_BIT\
			|EVENTS_AUX_STATUS_IO6_BIT|EVENTS_AUX_STATUS_IO7_BIT|EVENTS_AUX_STATUS_IO8_BIT|EVENTS_AUX_STATUS_9_NTC_BIT|EVENTS_AUX_STATUS_10_IBUS_BIT|EVENTS_AUX_STATUS_11_VBUS_BIT\
			|EVENTS_AUX_STATUS_12_K1_TEMPRATURE_BIT|EVENTS_AUX_STATUS_13_K2_TEMPRATURE_BIT|EVENTS_AUX_STATUS_14_EMERGENCY_KEY_BIT| EVENTS_AUX_STATUS_15_WATER_AIR_PREPARE_BIT |EVENTS_AUX_STATUS_16_CLEAN_BIT\
    )
//laserEvent02Handle
#define EVENTS_LASER_GX_TEST_PREPARE_OK_BIT  			0x01
//光纤激活
#define EVENTS_LASER_980_PREPARE_OK_BIT  					0x01<<1  //980laser
#define EVENTS_LASER_1064_PREPARE_OK_BIT        	0x01<<2   //1064laser
#define EVENTS_LASER_JT_ENABLE_BIT        	      0x01<<3   //脚踏开放

#define EVENTS_LASER_PREPARE_OK_ALL_BITS_MASK        	(EVENTS_LASER_JT_ENABLE_BIT|EVENTS_LASER_GX_TEST_PREPARE_OK_BIT|EVENTS_LASER_1064_PREPARE_OK_BIT|EVENTS_LASER_980_PREPARE_OK_BIT)

/* USER CODE END PD */

/* USER CODE BEGIN PM */

//static float voltage[16]={\
1.5,1.6,1.7,1.8,1.9,2.0,2.1,2.2,2.3,2.4,2.5,\
	2.7,2.9,3.1,3.5,3.8}
//static float jd_pulse_timeus[16]={\
	62,56,50,46.5,43,40,38,35.5,33.5,32,30.5,\
	28.5,26.5,25,22.5,20.5};
//1.5V~3.8V 0.1步进
//static unsigned short int  jdq_pulse_pro_timeUs[24]={\
  69,63,57,54,50,47,45,43,41,39,38,\
  37,36,34,33,32,31,31,30,30,30,29,28,27};
  //脉冲触发时间：电脉宽=脉冲触发时间+光脉宽+7(延长)
  static float jdq_100uspulse_energe_voltage[41]={//(0,5mJ~200mJ)
    0,1.43, 1.48, 1.6, 1.65, 1.69, 1.77, 1.84, 1.92, 2, 2.08, 2.14,\
    2.2, 2.29, 2.37, 2.43, 2.49, 2.55,2.63,2.70 , 2.77, 2.84, 2.89,\
    2.96, 3.03, 3.08, 3.13, 3.19, 3.25,3.32,3.39, 3.46, 3.53, 3.60,\
    3.66, 3.72, 3.78, 3.84, 3.89 ,  3.95,   4.01,
    //200mJ
  };
  static float jdq_120uspulse_energe_voltage[41]={//(0,5mJ~200mJ)
    0,1.42, 1.465, 1.53, 1.6, 1.66,1.7, 1.76, 1.828, 1.87,1.94, 2.01,\
    2.07, 2.135, 2.195, 2.25, 2.3, 2.365, 2.43, 2.48, 2.53, 2.58, 2.63,\
    2.68, 2.73, 2.78, 2.83, 2.89, 2.95, 3.01 , 3.07, 3.12, 3.18, 3.22,\
    3.26, 3.32, 3.375, 3.43, 3.48, 3.53, 3.58
    //200mJ
  };
  static float jdq_200uspulse_energe_voltage[81]={//(0,5mJ~400mJ)//暂定
    0,1.46, 1.49, 1.51, 1.54, 1.56, 1.62, 1.65, 1.64 , 1.67, 1.71,  1.75,\
    1.81,1.82, 1.85, 1.92, 1.94, 1.98, 2.00 , 2.04, 2.06,  2.1,  2.17,\
    2.18, 2.23, 2.24, 2.28, 2.29, 2.30 , 2.34, 2.36, 2.39, 2.43, 2.47,\
    2.49, 2.53, 2.55, 2.57, 2.61, 2.63,  2.67,//200mJJ
    2.6525,2.685,2.7175,2.75,2.7825,2.815,2.8475,2.88,
    2.9125,2.945,2.9775,3.01,3.0425,3.075,3.1075,3.14,3.1725,\
    3.205,3.2375,3.27,3.3025,3.335,3.3675,3.4,3.4325,3.465,3.4975,\
    3.53,3.5625,3.595,3.6275,3.66,3.6925,3.725,3.7575,3.79,3.8225,\
    3.855,3.8875,3.92
  };
  static float jdq_pulse_width_param[41]={//(0,5mJ~200mJ)//时间能量系数
    0,0.004,0.064,0.074,0.097,0.104,0.152,0.175,0.193,0.211,0.249,0.27,\
    0.304,0.306,0.335,0.356,0.395,0.419,0.439,0.47,0.506,0.518,0.553,\
    0.575, 0.606,0.625,0.645,0.696,0.721,0.738,0.773,0.793,0.816,0.849,\
    0.874,0.89, 0.929,0.957,0.978,1.01,1.034
  };
/* USER CODE END PM */

/* Definitions for defaultTask */
osThreadId_t defaultTaskHandle;
const osThreadAttr_t defaultTask_attributes = {
  .name = "defaultTask",
  .stack_size = 312 * 4,
  .priority = (osPriority_t) osPriorityHigh,
};
/* Definitions for myTask02 */
osThreadId_t myTask02Handle;
const osThreadAttr_t myTask02_attributes = {
  .name = "myTask02",
  .stack_size = 312 * 4,
  .priority = (osPriority_t) osPriorityNormal4,
};
/* Definitions for myTask03 */
osThreadId_t myTask03Handle;
const osThreadAttr_t myTask03_attributes = {
  .name = "myTask03",
  .stack_size = 160 * 4,
  .priority = (osPriority_t) osPriorityNormal7,
};
/* Definitions for myTask04 */
osThreadId_t myTask04Handle;
const osThreadAttr_t myTask04_attributes = {
  .name = "myTask04",
  .stack_size = 312 * 4,
  .priority = (osPriority_t) osPriorityNormal6,
};
/* Definitions for myTask05 */
osThreadId_t myTask05Handle;
const osThreadAttr_t myTask05_attributes = {
  .name = "myTask05",
  .stack_size = 256 * 4,
  .priority = (osPriority_t) osPriorityNormal5,
};
/* Definitions for myTask06 */
osThreadId_t myTask06Handle;
const osThreadAttr_t myTask06_attributes = {
  .name = "myTask06",
  .stack_size = 192 * 4,
  .priority = (osPriority_t) osPriorityNormal5,
};
/* Definitions for myTask07 */
osThreadId_t myTask07Handle;
const osThreadAttr_t myTask07_attributes = {
  .name = "myTask07",
  .stack_size = 256 * 4,
  .priority = (osPriority_t) osPriorityNormal5,
};
/* Definitions for myTask08 */
osThreadId_t myTask08Handle;
const osThreadAttr_t myTask08_attributes = {
  .name = "myTask08",
  .stack_size = 128 * 4,
  .priority = (osPriority_t) osPriorityNormal7,
};
/* Definitions for myTask09 */
osThreadId_t myTask09Handle;
const osThreadAttr_t myTask09_attributes = {
  .name = "myTask09",
  .stack_size = 256 * 4,
  .priority = (osPriority_t) osPriorityNormal5,
};
/* Definitions for myTask10 */
osThreadId_t myTask10Handle;
const osThreadAttr_t myTask10_attributes = {
  .name = "myTask10",
  .stack_size = 256 * 4,
  .priority = (osPriority_t) osPriorityNormal4,
};
/* Definitions for myTask11 */
osThreadId_t myTask11Handle;
const osThreadAttr_t myTask11_attributes = {
  .name = "myTask11",
  .stack_size = 128 * 4,
  .priority = (osPriority_t) osPriorityNormal4,
};
/* Definitions for jdqGWB3200wTask */
osThreadId_t jdqGWB3200wTaskHandle;
const osThreadAttr_t jdqGWB3200wTask_attributes = {
  .name = "jdqGWB3200wTask",
  .stack_size = 256 * 4,
  .priority = (osPriority_t) osPriorityNormal5,
};
/* Definitions for rgbQueue02 */
osMessageQueueId_t rgbQueue02Handle;
const osMessageQueueAttr_t rgbQueue02_attributes = {
  .name = "rgbQueue02"
};
/* Definitions for musicQueue03 */
osMessageQueueId_t musicQueue03Handle;
const osMessageQueueAttr_t musicQueue03_attributes = {
  .name = "musicQueue03"
};
/* Definitions for keyJTMessageQueue01 */
osMessageQueueId_t keyJTMessageQueue01Handle;
const osMessageQueueAttr_t keyJTMessageQueue01_attributes = {
  .name = "keyJTMessageQueue01"
};
/* Definitions for jdqGwb3200CtrMessageQueue04 */
osMessageQueueId_t jdqGwb3200CtrMessageQueue04Handle;
uint8_t jdqGwb3200CtrMessageQueue04Buffer[ 3 * 8 ];
osStaticMessageQDef_t jdqGwb3200CtrMessageQueue04ControlBlock;
const osMessageQueueAttr_t jdqGwb3200CtrMessageQueue04_attributes = {
  .name = "jdqGwb3200CtrMessageQueue04",
  .cb_mem = &jdqGwb3200CtrMessageQueue04ControlBlock,
  .cb_size = sizeof(jdqGwb3200CtrMessageQueue04ControlBlock),
  .mq_mem = &jdqGwb3200CtrMessageQueue04Buffer,
  .mq_size = sizeof(jdqGwb3200CtrMessageQueue04Buffer)
};
/* Definitions for laserWorkTimer01 */
osTimerId_t laserWorkTimer01Handle;
const osTimerAttr_t laserWorkTimer01_attributes = {
  .name = "laserWorkTimer01"
};
/* Definitions for cleanTimer02 */
osTimerId_t cleanTimer02Handle;
const osTimerAttr_t cleanTimer02_attributes = {
  .name = "cleanTimer02"
};
/* Definitions for tmcMaxRunTimer03 */
osTimerId_t tmcMaxRunTimer03Handle;
const osTimerAttr_t tmcMaxRunTimer03_attributes = {
  .name = "tmcMaxRunTimer03"
};
/* Definitions for jdqHeart100msTimer04 */
osTimerId_t jdqHeart100msTimer04Handle;
const osTimerAttr_t jdqHeart100msTimer04_attributes = {
  .name = "jdqHeart100msTimer04"
};
/* Definitions for powerOffBinarySem02 */
osSemaphoreId_t powerOffBinarySem02Handle;
const osSemaphoreAttr_t powerOffBinarySem02_attributes = {
  .name = "powerOffBinarySem02"
};
/* Definitions for laserPrapareReqSem03 */
osSemaphoreId_t laserPrapareReqSem03Handle;
const osSemaphoreAttr_t laserPrapareReqSem03_attributes = {
  .name = "laserPrapareReqSem03"
};
/* Definitions for laserCloseSem05 */
osSemaphoreId_t laserCloseSem05Handle;
const osSemaphoreAttr_t laserCloseSem05_attributes = {
  .name = "laserCloseSem05"
};
/* Definitions for hmiCanBusIdleSem06 */
osSemaphoreId_t hmiCanBusIdleSem06Handle;
const osSemaphoreAttr_t hmiCanBusIdleSem06_attributes = {
  .name = "hmiCanBusIdleSem06"
};
/* Definitions for jdqHeart100msBinarySem05 */
osSemaphoreId_t jdqHeart100msBinarySem05Handle;
const osSemaphoreAttr_t jdqHeart100msBinarySem05_attributes = {
  .name = "jdqHeart100msBinarySem05"
};
/* Definitions for aux1SHeartBinarySem06 */
osSemaphoreId_t aux1SHeartBinarySem06Handle;
const osSemaphoreAttr_t aux1SHeartBinarySem06_attributes = {
  .name = "aux1SHeartBinarySem06"
};
/* Definitions for auxStatusEvent01 */
osEventFlagsId_t auxStatusEvent01Handle;
osStaticEventGroupDef_t auxStatusEvent01ControlBlock;
const osEventFlagsAttr_t auxStatusEvent01_attributes = {
  .name = "auxStatusEvent01",
  .cb_mem = &auxStatusEvent01ControlBlock,
  .cb_size = sizeof(auxStatusEvent01ControlBlock),
};
/* Definitions for laserEvent02 */
osEventFlagsId_t laserEvent02Handle;
osStaticEventGroupDef_t laserEvent02ControlBlock;
const osEventFlagsAttr_t laserEvent02_attributes = {
  .name = "laserEvent02",
  .cb_mem = &laserEvent02ControlBlock,
  .cb_size = sizeof(laserEvent02ControlBlock),
};

/* USER CODE BEGIN FunctionPrototypes */
unsigned  int app_get_cali_devid(void);
void app_set_default_sys_config_param(void);
void app_sys_genaration_status_manage(void);
void app_sys_param_load(void);
unsigned char app_sys_param_save_data(void);
void app_air_pump_manage(unsigned char air_level);
void app_pwr_gx_semo(unsigned char code);
void app_fresh_laser_status_param(void);
unsigned short int  app_laser_1064_energe_to_voltage(unsigned short int energe);
unsigned short int app_hmi_package_check(unsigned char* pBuff,unsigned short int buffLen) ;
void app_t_clean_run_timer(unsigned char *runflag);
void app_treatment_water_prepare(unsigned char *ctrflag,unsigned int runtimeMs);
void app_buzz_music(music_type  music_num,unsigned char volume);
void app_jdq_restart(void);
void app_sram_status_monitor( void );
#ifdef ONE_WIRE_BUS_SLAVE
unsigned int  app_owb_key_scan(unsigned short int timeMs);
#endif
float  app_energe_vdac(unsigned short int energe,unsigned short int pulseWidthUs);
/* USER CODE END FunctionPrototypes */

void StartDefaultTask(void *argument);
void auxTask02(void *argument);
void keyScanTask03(void *argument);
void laserWorkTask04(void *argument);
void fastAuxTask05(void *argument);
void hmiAppTask06(void *argument);
void canReceiveTask07(void *argument);
void powerOffTask08(void *argument);
void laserProhotTask09(void *argument);
void ge2117ManageTask10(void *argument);
void musicTask11(void *argument);
void jdqGWB3200wTask12(void *argument);
void LaserWorkTimerCallback01(void *argument);
void cleanWaterCallback02(void *argument);
void tmcMaxRunTimesCallback03(void *argument);
void jdqHeart100msCallback04(void *argument);

void MX_FREERTOS_Init(void); /* (MISRA C 2004 rule 8.1) */

/* Hook prototypes */
void vApplicationIdleHook(void);

/* USER CODE BEGIN 2 */
void vApplicationIdleHook( void )
{
   /* vApplicationIdleHook() will only be called if configUSE_IDLE_HOOK is set
   to 1 in FreeRTOSConfig.h. It will be called on each iteration of the idle
   task. It is essential that code added to this hook function never attempts
   to block in any way (for example, call xQueueReceive() with a block time
   specified, or call vTaskDelay()). If the application makes use of the
   vTaskDelete() API function (as this demo application does) then it is also
   important that vApplicationIdleHook() is permitted to return to its calling
   function, because it is the responsibility of the idle task to clean up
   memory allocated by the kernel to any task that has since been deleted. */
  // osThreadGetState(defaultTaskHandle);
   #ifdef IWDG_USED
   HAL_IWDG_Refresh(&hiwdg1);
   #endif
}
/* USER CODE END 2 */

void MX_FREERTOS_Init(void) {

  /* Create the semaphores(s) */
  /* creation of powerOffBinarySem02 */
  powerOffBinarySem02Handle = osSemaphoreNew(1, 0, &powerOffBinarySem02_attributes);

  /* creation of laserPrapareReqSem03 */
  laserPrapareReqSem03Handle = osSemaphoreNew(1, 0, &laserPrapareReqSem03_attributes);

  /* creation of laserCloseSem05 */
  laserCloseSem05Handle = osSemaphoreNew(1, 0, &laserCloseSem05_attributes);

  /* creation of hmiCanBusIdleSem06 */
  hmiCanBusIdleSem06Handle = osSemaphoreNew(1, 0, &hmiCanBusIdleSem06_attributes);

  /* creation of jdqHeart100msBinarySem05 */
  jdqHeart100msBinarySem05Handle = osSemaphoreNew(1, 0, &jdqHeart100msBinarySem05_attributes);

  /* creation of aux1SHeartBinarySem06 */
  aux1SHeartBinarySem06Handle = osSemaphoreNew(1, 0, &aux1SHeartBinarySem06_attributes);

  /* Create the timer(s) */
  /* creation of laserWorkTimer01 */
  laserWorkTimer01Handle = osTimerNew(LaserWorkTimerCallback01, osTimerOnce, NULL, &laserWorkTimer01_attributes);

  /* creation of cleanTimer02 */
  cleanTimer02Handle = osTimerNew(cleanWaterCallback02, osTimerOnce, NULL, &cleanTimer02_attributes);

  /* creation of tmcMaxRunTimer03 */
  tmcMaxRunTimer03Handle = osTimerNew(tmcMaxRunTimesCallback03, osTimerOnce, NULL, &tmcMaxRunTimer03_attributes);

  /* creation of jdqHeart100msTimer04 */
  jdqHeart100msTimer04Handle = osTimerNew(jdqHeart100msCallback04, osTimerPeriodic, NULL, &jdqHeart100msTimer04_attributes);

  /* Create the queue(s) */
  /* creation of rgbQueue02 */
  rgbQueue02Handle = osMessageQueueNew (3, sizeof(uint16_t), &rgbQueue02_attributes);

  /* creation of musicQueue03 */
  musicQueue03Handle = osMessageQueueNew (3, sizeof(uint16_t), &musicQueue03_attributes);

  /* creation of keyJTMessageQueue01 */
  keyJTMessageQueue01Handle = osMessageQueueNew (3, sizeof(uint16_t), &keyJTMessageQueue01_attributes);

  /* creation of jdqGwb3200CtrMessageQueue04 */
  jdqGwb3200CtrMessageQueue04Handle = osMessageQueueNew (3, 8, &jdqGwb3200CtrMessageQueue04_attributes);

  /* Create the thread(s) */
  /* creation of defaultTask */
  defaultTaskHandle = osThreadNew(StartDefaultTask, NULL, &defaultTask_attributes);

  /* creation of myTask02 */
  myTask02Handle = osThreadNew(auxTask02, NULL, &myTask02_attributes);

  /* creation of myTask03 */
  myTask03Handle = osThreadNew(keyScanTask03, NULL, &myTask03_attributes);

  /* creation of myTask04 */
  myTask04Handle = osThreadNew(laserWorkTask04, NULL, &myTask04_attributes);

  /* creation of myTask05 */
  myTask05Handle = osThreadNew(fastAuxTask05, NULL, &myTask05_attributes);

  /* creation of myTask06 */
  myTask06Handle = osThreadNew(hmiAppTask06, NULL, &myTask06_attributes);

  /* creation of myTask07 */
  myTask07Handle = osThreadNew(canReceiveTask07, NULL, &myTask07_attributes);

  /* creation of myTask08 */
  myTask08Handle = osThreadNew(powerOffTask08, NULL, &myTask08_attributes);

  /* creation of myTask09 */
  myTask09Handle = osThreadNew(laserProhotTask09, NULL, &myTask09_attributes);

  /* creation of myTask10 */
  myTask10Handle = osThreadNew(ge2117ManageTask10, NULL, &myTask10_attributes);

  /* creation of myTask11 */
  myTask11Handle = osThreadNew(musicTask11, NULL, &myTask11_attributes);

  /* creation of jdqGWB3200wTask */
  jdqGWB3200wTaskHandle = osThreadNew(jdqGWB3200wTask12, NULL, &jdqGWB3200wTask_attributes);

  /* Create the event(s) */
  /* creation of auxStatusEvent01 */
  auxStatusEvent01Handle = osEventFlagsNew(&auxStatusEvent01_attributes);

  /* creation of laserEvent02 */
  laserEvent02Handle = osEventFlagsNew(&laserEvent02_attributes);

}

/* USER CODE BEGIN Header_StartDefaultTask */
/**
  * @brief  Function imp
  *
  * lementing the defaultTask thread.
  * @param  argument: Not used
  *     typedef struct {
      unsigned char systemParamFlag;                        //系统参数，0未加载；1待机；2开启；3异常；
      unsigned char jtFlag;                                 //脚踏输入，0未加载；1待机；2开启；3异常；
      unsigned char rgbFlag;                                //rgb氛围灯，0未加载；1待机；2开启；3异常；
      unsigned char auxiliary_bulbFlag;                     //激光指示灯，0未加载；1待机；2开启；3异常；
      unsigned char hmiLcdLoadFlag;                         //显示屏，0未加载；1待机；2开启；3异常；
      unsigned char coolWaterSystemLoadFlag;                //冷却水系统，0未加载；1待机；2开启；3异常；
      unsigned char treatmentWaterSystemLoadFlag;           //治疗水系统，0未加载；1待机；2开启；3异常；
      unsigned char tempratureSystemLoadFlag;               //温度系统，0未加载；1待机；2开启；3异常；
      unsigned char eTempratureAirpressureSystemLoadFlag;   //环境温度气压系统，0未加载；1待机；2开启；3异常；
      unsigned char airPressureSystemLoad
      Flag;              //气压系统，0未加载；1待机；2开启；3异常；
      unsigned char laserPowerSystemLoadFlag;               //激光电源系统，0未加载；1待机；2开启；3异常；
    }__attribute__ ((packed)) SYS_LOAD_STATUS;//辅助系统加载状态
  * @retval None
  */
/* USER CODE END Header_StartDefaultTask */
void StartDefaultTask(void *argument)
{
  /* USER CODE BEGIN StartDefaultTask */
  /* Infinite loop */
  uint32_t timeout;
  uint8_t load_sta;
  float treatmentWaterC;
  app_air_pump_switch( DISABLE);
  app_mcu_power_switch(ENABLE);
  app_lcd_power_12V_switch(ENABLE);
  for(;;)
  {
    //load
    HAL_TIMEx_PWMN_Start(&htim15,TIM_CHANNEL_1);
    app_beep_pwm(music_tab_c[14],50);
    HAL_Delay(400);
    app_beep_pwm(0,0);
    do
		{
			HAL_Delay(200);//beep
			DEBUG_PRINTF("please release power key%d\r\n",HAL_GPIO_ReadPin(KEY_PWR_SWITCH_GPIO_Port,KEY_PWR_SWITCH_Pin));
		}while(HAL_GPIO_ReadPin(KEY_PWR_SWITCH_GPIO_Port,KEY_PWR_SWITCH_Pin)==GPIO_PIN_RESET);

    DEBUG_PRINTF("load system config param\r\n");
    EEPROM_M24C32_init();
    app_sys_param_load();
    DEBUG_PRINTF("DEVICEID=%x\r\n",u_sys_param.sys_config_param.equipmentId);
    DEBUG_PRINTF("load hmi lcd power...\r\n");
    app_lcd_power_12V_switch(ENABLE);
    DEBUG_PRINTF("load rgb...  \r\n");
    IS3_init();
    load_sta=0;
    DEBUG_PRINTF("load cool compressor ...\r\n");
    ge2117_UART_Init(9600);
    DEBUG_PRINTF("load circle water system...\r\n");
    app_circle_water_pump_switch( ENABLE );
    timeout=0;
    do
    {
      HAL_Delay(100);
      timeout+=100;
      if(timeout>5000)
      {
        app_circle_water_pump_switch( DISABLE);
        DEBUG_PRINTF("load circle load fail  \r\n");
        load_sta=3;//err
        break;
      }
    }while(app_get_io_status(In8_water_circle_ok)!=SUCCESS);
    if(load_sta==0)
    {
      DEBUG_PRINTF("load circle load ok  \r\n");
    }
    load_sta = 0;
    DEBUG_PRINTF("load enciroment airpressure system...\r\n");
    GZP6816D_init();
    GZP6816D_start_sampling();
    timeout = 0;
    do
    {
      HAL_Delay(300);
      timeout+=300;
      if(timeout>2000)
      {
        DEBUG_PRINTF("eViromentAirPressure load fail \r\n");
        sEnvParam.air_gzp_enviroment_pressure_kpa=94.0;
        load_sta=3;// err
        break;
      }
    }while(GZP6816D_IsBusy()!=0);
    if(load_sta==0)
    {
      GZP6816D_get_cal(&sEnvParam.air_gzp_enviroment_pressure_kpa,&sEnvParam.enviroment_temprature);
      DEBUG_PRINTF("eViromentAirPressure load ok %.2f kPa  eviroment temprature =%.1f ℃\r\n",sEnvParam.air_gzp_enviroment_pressure_kpa,sEnvParam.enviroment_temprature);
    }
    load_sta=0;
    DEBUG_PRINTF("load cool tmprature  measure system...\r\n");
		max_31865_pt1000();
    HAL_Delay(300);//50HZ
    float temp_t_f=Get_pt_tempture();
		if(temp_t_f<60.0&&temp_t_f>-40.0)
		{
			sEnvParam.eth_k1_temprature = temp_t_f;
			sEnvParam.eth_k2_temprature = temp_t_f;
		}
		else
		{
			sEnvParam.eth_k1_temprature= 25.5; //err
			sEnvParam.eth_k2_temprature = 25.0;
			load_sta=1;
		}
    if(load_sta==0)
    {
      DEBUG_PRINTF("PT1000 load ok k1_T=%.1f k2_T=%.1f \r\n",sEnvParam.eth_k1_temprature,sEnvParam.eth_k2_temprature);
    }
    else DEBUG_PRINTF("PT1000 load fail  \r\n");
    /***********NTC,laser_energe,iBus,vBus,air_pump_pressure气泵气压，参数****************** */
    app_start_multi_channel_adc();
    DEBUG_PRINTF("load adc sampling NTC ,laserenergetic,iBus,vbus,air pressure...\r\n");
    HAL_Delay(100);//wait >64ms
    app_get_adc_value(AD1_NTC_INDEX,&sEnvParam.NTC_temprature);
   // app_get_adc_value(AD2_LASER_1064_INDEX,&sEnvParam.laser_1064_energy);
    app_get_adc_value(AD1_OCP_Ibus_INDEX,&sEnvParam.iBus);
    app_get_adc_value(AD1_24V_VBUS_INDEX,&sEnvParam.vBus);
    app_get_adc_value(AD1_AIR_PRESSER_INDEX,&sEnvParam.air_pump_pressure);
    app_get_adc_value(AD1_WATER_PRESSER_INDEX,&sEnvParam.treatment_water_pressure);
    DEBUG_PRINTF("adc load:NTC=%.2f℃ laser_energe=%.1f iBus=%.1fmA ,vBus=%.1fmV,air_pump_pressure=%.2fkPa,water_pressure=%.2fkPa\r\n",sEnvParam.NTC_temprature,\
      sEnvParam.laser_1064_energy,sEnvParam.iBus,sEnvParam.vBus,sEnvParam.air_pump_pressure,sEnvParam.treatment_water_pressure);

    if(sEnvParam.NTC_temprature>-40&&sEnvParam.NTC_temprature<150)
    {
      DEBUG_PRINTF("adc load:NTC_ad_channel ok=%.2f℃\r\n",sEnvParam.NTC_temprature);
    }
    else
    {
      DEBUG_PRINTF("adc load:NTC_ad_channel error\r\n");
    }
    if(sEnvParam.laser_1064_energy>50)
    {
      DEBUG_PRINTF("adc load:laser_1064_energy_ad_channel error\r\n");
    }
    if(sEnvParam.iBus>MAX_IBUS_MA)
    {
      DEBUG_PRINTF("adc load:ibus_ad_channel error\r\n");
    }
    else
    {
      DEBUG_PRINTF("adc load:ibus_ad_channel ok=%.2fmA\r\n",sEnvParam.iBus);
    }
    if(sEnvParam.vBus<MIN_VBUS_MV)
    {
      DEBUG_PRINTF("adc load:vbus_ad_channel error\r\n");
    }
    else
    {
      DEBUG_PRINTF("adc load:vbus_ad_channel ok=%.2fmV\r\n",sEnvParam.vBus);
    }
    if(sEnvParam.air_pump_pressure+20<sEnvParam.air_gzp_enviroment_pressure_kpa)
    {
      DEBUG_PRINTF("adc load:air_pressure_ad_channel error\r\n");
    }
    else
    {
      DEBUG_PRINTF("adc load:air_pressure_ad_channel ok=%.2fkPa\r\n",sEnvParam.air_pump_pressure);
    }
    load_sta = 0;
    float s_jdq_set_voltage,s_jdq_set_current;
    DEBUG_PRINTF("load laser jdq power system ... \r\n");
    jdq_init();
    #ifdef JDQ_PWR_GWB_3200W
    HAL_Delay(JDQ_RS485_FRAME_MAX_DELAY_MS);
    HAL_Delay(JDQ_RS485_FRAME_MAX_DELAY_MS);
    app_jdq_bus_get_v_c_req();
    timeout = 0;
    do
    {
      HAL_Delay(JDQ_RS485_FRAME_MIN_MS);
      timeout+=JDQ_RS485_FRAME_MIN_MS;
    }while(app_get_jdq_rs485_bus_statu()!=0&&timeout<JDQ_RS485_FRAME_MAX_DELAY_MS);
    if(app_jdq_gwb_pwr_flag()!=0)
    {
      DEBUG_PRINTF("lasr jdq  load ok jdq_v=%.1f v \r\n",app_jdq_voltage_monitor());
      HAL_Delay(JDQ_RS485_FRAME_MAX_DELAY_MS);
      app_jdq_bus_power_on_off(0);
      timeout = 0;
      do
      {
        HAL_Delay(JDQ_RS485_FRAME_MIN_MS);
        timeout+=JDQ_RS485_FRAME_MIN_MS;
      }while(app_get_jdq_rs485_bus_statu()!=0&&timeout<JDQ_RS485_FRAME_MAX_DELAY_MS);
      load_sta = 1;
    }
    else
    {
      load_sta=3;
      DEBUG_PRINTF("laser jdq  load fail \r\n");
    }
  #endif
    app_laser_pulse_start(LASER_PULSE_STOP, LASER_PULSE_STOP,LASER_PULSE_STOP);
    load_sta=0;
    DEBUG_PRINTF("load treatment water system...\r\n");
    tmc2226_init();
    if(app_get_io_status(In7_water_ready_ok)!=SUCCESS)
    {
      tmc2226_start(TMC_WATER_OUT_DIR_VALUE,3,CONTINUOUS_STEPS_COUNT );
    }
    timeout=0;
    do
    {
      HAL_Delay(50);
      timeout+=50;
      app_get_adc_value(AD1_WATER_PRESSER_INDEX,&sEnvParam.treatment_water_pressure);
      if(timeout>5000)
      {
        DEBUG_PRINTF("treatment water load fail \r\n");
        load_sta=3;
        break;
      }
    }while(app_get_io_status(In7_water_ready_ok)!=SUCCESS);
    tmc2226_stop();
    if(load_sta==0)
    {
      load_sta=1;
      DEBUG_PRINTF(" treatment water load ok \r\n");
    }
    #ifdef IWDG_USED
    MX_IWDG1_Init();
    #endif
    osThreadTerminate(defaultTaskHandle);
   //osDelay(1);
  }
  /* USER CODE END StartDefaultTask */
}

void auxTask02(void *argument)
{
  /* USER CODE BEGIN auxTask02 */
  /* Infinite loop */
	uint16_t rgbRun=1;
  unsigned int circle_count=0,T;
  fan_init();
  sGenSta.laser_param_B01_energe_status=1;//激光能量状态，0未加载；1待机；2开启；3异常；
  for(;;)
  {
    osStatus_t m_sta=osSemaphoreAcquire(aux1SHeartBinarySem06Handle,5);
    if(m_sta==osOK)
    {
      /***********环境气压、温度监测*******************/
      unsigned char  status=app_gzp6816d_listen(1000,&sEnvParam.air_gzp_enviroment_pressure_kpa,&sEnvParam.enviroment_temprature);
      if(status!=0) sEnvParam.air_gzp_enviroment_pressure_kpa =95.0;//error
      app_fan_manage(1000);
      HAL_GPIO_TogglePin(MCU_SYS_health_LED_GPIO_Port,MCU_SYS_health_LED_Pin);
      //app_sram_status_monitor();
      //DEBUG_PRINTF("air_pressure=%.2fkPa water_pressure=%.2fkPa\r\n",sEnvParam.air_pump_pressure,sEnvParam.treatment_water_pressure);
    }
		/**********************RGB****************************/
		osStatus_t rgb_s=osMessageQueueGet(rgbQueue02Handle,&rgbRun,0,5);
    switch(rgbRun)
    {
      case 0:
        rgb_color_all(0);
      break;
      case RGB_G_STANDBY:
        {
          if(u_sys_param.sys_config_param.rgb_light==0)  T=0;
          else if(u_sys_param.sys_config_param.rgb_light<6) T=400;//最小亮度
          else T=(2000/(u_sys_param.sys_config_param.rgb_light));
          circle_count+=10;
          if(circle_count>T)
          {
            circle_count = 0;
            Green_Breath(u_sys_param.sys_config_param.rgb_light);
            //T=(2560/(1.28*u_sys_param.sys_config_param.rgb_light)
            //T=(2000/(u_sys_param.sys_config_param.rgb_light));
          }
          osDelay(10);
        }
      break;
      case RGB_LASER_PREPARE_OK:
        {
          rgb_color_all(2);
        }
      break;
      case RGB_LASER_WORK_STATUS:
        app_rgb_breath_ctl(laser_ctr_param.laserFreq,9);
      break;
      default:
        rgb_color_all(0);
      break;
    }
    osDelay(1);
  }
  /* USER CODE END auxTask02 */
}

void keyScanTask03(void *argument)
{
  /* USER CODE BEGIN keyScanTask03 */
   unsigned int recKeyValue,rf24KeyValue;
   app_key_message key_message;
   static app_key_message history_key_message;
   RF24_init();
   #ifdef ONE_WIRE_BUS_JT_SLAVE
   one_wire_bus_init();
   #endif
   /*Infinite loop */
   for(;;)
   {
     osDelay(50);
     recKeyValue = app_IO_key_scan(50);
     rf24KeyValue  = app_RF24_key_scan(50);
     if(u_sys_param.sys_config_param.jt_status!=0&&sEnvParam.JT_ID==u_sys_param.sys_config_param.jtId)
     {
       if((recKeyValue&0XFF)==IO_KEY_IDLE)
       {
         if(rf24KeyValue!=KEY_NO_CONNECT)
         {
           recKeyValue|=rf24KeyValue;
         }
       }
       else if((recKeyValue&0XFF)==KEY_NO_CONNECT)
       {
         recKeyValue&=0xFF00;
         recKeyValue|=rf24KeyValue;
       }
     }
     else
     {
       recKeyValue&=0xFF00;
     }
     key_message=app_key_value_analysis(recKeyValue);
     if(key_message==key_pwr_long_press)
     {
       osSemaphoreRelease(powerOffBinarySem02Handle);
       key_message = NO_KEY_MESSAGE;
       history_key_message=key_message;
     }
     else
     {
       if(app_remote_key_sta()==ERROR)
       {
         if(sGenSta.laser_param_B7_ykls_status!=0)
         {
          DEBUG_PRINTF("JT remote locked\r\n");
          sGenSta.laser_param_B7_ykls_status = 0;
         }
         if(history_key_message!=key_jt_release)
         {
           if(osMessageQueuePut(keyJTMessageQueue01Handle,&history_key_message,0,0)==osOK)
           {
             history_key_message = key_jt_release;
             key_message = NO_KEY_MESSAGE;
           }
         }
       }
       else
       {
         sGenSta.laser_param_B7_ykls_status=1;//release
         if(key_message!=NO_KEY_MESSAGE)
         {
           if(osEventFlagsGet(laserEvent02Handle)!=0)
           {
             if(osMessageQueuePut(keyJTMessageQueue01Handle,&key_message,0,0)==osOK)
             {  //DEBUG_PRINTF("JT key press %d\r\n",key_message);
               history_key_message = key_message;
               key_message =	NO_KEY_MESSAGE;
             }
           }
           else
           {
             if(history_key_message!=key_jt_release)
             {
               if(osMessageQueuePut(keyJTMessageQueue01Handle,&history_key_message,0,0)==osOK)
               { //DEBUG_PRINTF("JT key press %d\r\n",key_message);
                 history_key_message = key_jt_release;
                 key_message =	NO_KEY_MESSAGE;
               }
             }
           }
         }
       }
     }
   }
  /* USER CODE END keyScanTask03 */
}

void laserWorkTask04(void *argument)
{
  /* USER CODE BEGIN laserWorkTask04 */
  /* Infinite loop */
  uint8_t recKeyMessage;
	uint16_t rgbMessage;	//0关闭//1待机绿色2：准备OK紫色常亮；3脉冲输出紫色呼吸
	uint32_t timeout=0;
  osStatus_t statusJT;
  float local_f,e_feedback,fisrt_pulse_cali;//首脉冲校准
	LASER_CONTROL_PARAM *pLaserConfig;
	pLaserConfig = &laser_ctr_param;
  uint32_t event;
  osStatus_t laser_close_sem;
  U_G3200W_CTR_MESSAGE g_ctr_tx_msg;
  osStatus_t gwb_ctr_tx_sta;
  int32_t e_cali_timeout= 0;
  for(;;)
  {
    event=osEventFlagsWait(laserEvent02Handle,EVENTS_LASER_PREPARE_OK_ALL_BITS_MASK,osFlagsNoClear,portMAX_DELAY);
    statusJT= osMessageQueueGet(keyJTMessageQueue01Handle,&recKeyMessage,0,10);
    if(event==(EVENTS_LASER_1064_PREPARE_OK_BIT|EVENTS_LASER_JT_ENABLE_BIT))
    {
      if(recKeyMessage==key_jt_long_press&&sGenSta.laser_run_B0_pro_hot_status!=0&&sGenSta.laser_run_B5_timer_status==0)
      {
        if(sGenSta.laser_run_B1_laser_out_status==0)
        {
          if(laser_ctr_param.timerEnableFlag!=0&&laser_ctr_param.timerCtr!=0)  {
            osTimerStart(laserWorkTimer01Handle,laser_ctr_param.timerCtr*SYS_1_SECOND_TICKS);
          }
          local_f  =  app_energe_vdac(laser_ctr_param.laserEnerge,u_sys_param.sys_config_param.laser_pulse_width_us);

          #if 0
          //test
          local_f = laser_ctr_param.ledLightLevel*0.025+DAC_MIN_VOLTAGE_F;
          #endif
          if(pLaserConfig->proCali==0&&laser_ctr_param.ctrTestMode==0)
          {
            if(pLaserConfig->treatmentWaterLevel!=0||pLaserConfig->airPressureLevel!=0)
            {
              app_deflate_air_solenoid(ENABLE);
              if( pLaserConfig->treatmentWaterLevel!=0) tmc2226_start(TMC_WATER_OUT_DIR_VALUE,laser_ctr_param.treatmentWaterLevel,CONTINUOUS_STEPS_COUNT);
            }
          }
          else
          {
            laser_ctr_param.laserFreq = 10;
          }
          DEBUG_PRINTF("e=%dev=%.3f freq=%d timeU=%d\r\n",laser_ctr_param.laserEnerge,local_f,laser_ctr_param.laserFreq,u_sys_param.sys_config_param.laser_pulse_width_us);
          if(local_f<1.8)
          { //光电管增益
            laser_ctr_param.lowEnergeMode=1;
            app_opa_gain_control_switch( ENABLE);
          }
          else{
            app_opa_gain_control_switch( DISABLE);
            laser_ctr_param.lowEnergeMode=0;
          }
         // fisrt_pulse_cali=1.8;
          fisrt_pulse_cali=local_f;// local_f*0.4+DAC_MIN_VOLTAGE_F*0.6;
          AD5541A_SetVoltage(fisrt_pulse_cali,4.096); //首脉冲
          fisrt_pulse_cali = 0;
          sGenSta.laser_run_B1_laser_out_status = 1;
          rgbMessage = RGB_LASER_WORK_STATUS;
          osMessageQueuePut(rgbQueue02Handle,&rgbMessage,0,0);
          app_laser_pulse_start(u_sys_param.sys_config_param.laser_pulse_width_us,laser_ctr_param.laserFreq,local_f);
        }
        else
        {
          #if 1//energe moniter
          if(sGenSta.laser_run_B1_laser_out_status!=0&&statusJT==osOK) //cali
          {
            app_get_adc_value( AD2_LASER_1064_INDEX,&e_feedback);
            float p_peak;
            if( laser_ctr_param.lowEnergeMode==0)   p_peak = (e_feedback*0.000825);//peak  power
            else p_peak = (e_feedback*0.000405);//peak  power 4倍
            //float ene_average_p= (p_peak)*u_sys_param.sys_config_param.laser_pulse_width_us*laser_ctr_param.laserFreq;//pavg  power
            //E=p_avg_peak/laser_ctr_param.laserFreq;
            sEnvParam.laser_1064_energy=p_peak*u_sys_param.sys_config_param.laser_pulse_width_us;
            #if 1	//动态调整
            ///**温度补偿 */
            float  e_T=0;  //温度补偿
            if(sEnvParam.eth_k1_temprature<24.0)
            {
              if(sEnvParam.laser_1064_energy<25)
              {
                e_T=+0.10*(24.0-sEnvParam.eth_k1_temprature);//0.90
              }
              else  e_T=+0.06*(24.0-sEnvParam.eth_k1_temprature);//0.90
            }
            else // if(sEnvParam.eth_k1_temprature>=24.0)
            {
              if(sEnvParam.eth_k1_temprature>30)
              {
                e_T=-0.06;//1.08
              }
              else
              {
                e_T=-0.01*(sEnvParam.eth_k1_temprature-24.0);
              }
            }
            float laser_energy_T_cali;
            laser_energy_T_cali = sEnvParam.laser_1064_energy*(1-e_T);
            sEnvParam.laser_1064_energy=laser_energy_T_cali;
            /**温度补偿结束 */
            if(sEnvParam.laser_1064_energy>0&&laser_ctr_param.laserEnerge>0&&statusJT==osOK)
            {
              DEBUG_PRINTF("loac_f=%.1f energe=%.1f feedBck=%.1fmV pulseCount=%d rdb=%d 980=%d\r\n",local_f,sEnvParam.laser_1064_energy,e_feedback,u_sys_param.sys_config_param.laser_pulse_count,u_sys_param.sys_config_param.RDB_use_timeS,u_sys_param.sys_config_param.laser_use_timeS);
							if(sEnvParam.laser_1064_energy>5+laser_ctr_param.laserEnerge||sEnvParam.laser_1064_energy+5<laser_ctr_param.laserEnerge)
							{
							  if(sEnvParam.laser_1064_energy>5+laser_ctr_param.laserEnerge)
								{
                  e_cali_timeout++;
                  if(e_cali_timeout>3)  {
                    e_cali_timeout = 0;
                    fisrt_pulse_cali += 0.025;
                   // local_f  -=	fisrt_pulse_cali;
                  }
								}
								else if(sEnvParam.laser_1064_energy+5<laser_ctr_param.laserEnerge)
								{
                  e_cali_timeout--;
                  if(e_cali_timeout<-3)  {
                    e_cali_timeout = 0;
                    fisrt_pulse_cali+=0.025;
                   // local_f +=	fisrt_pulse_cali;
                  }
								}
								if(sGenSta.laser_run_B1_laser_out_status!=0&&fisrt_pulse_cali!=0) //genera
								{
									if(fisrt_pulse_cali>DAC_MAX_VOLTAGE_F) fisrt_pulse_cali=DAC_MAX_VOLTAGE_F;
									if(fisrt_pulse_cali<DAC_MIN_VOLTAGE_F) fisrt_pulse_cali=DAC_MIN_VOLTAGE_F;
                  if(local_f<1.8) laser_ctr_param.lowEnergeMode = 1;
                  else laser_ctr_param.lowEnergeMode = 0;
                  //AD5541A_SetVoltage(local_f, 4.096);
                 // app_laser_pulse_width_set(u_sys_param.sys_config_param.laser_pulse_width_us*10,local_f);
									fisrt_pulse_cali = 0;
								}
							}
							#endif
              if(sEnvParam.laser_1064_energy>ENERGE_MAX_VALUE+30)//laser_ctr_param.laserEnerge*1.30)
              {
                sGenSta.laser_param_B01_energe_status = 2; //over load
              }
              else sGenSta.laser_param_B01_energe_status = 1;
            }
            else
            {
              sGenSta.laser_param_B01_energe_status = 1;// 0;//err
            }
          }
          #else
          if(sGenSta.laser_run_B1_laser_out_status!=0)
          {
            sEnvParam.laser_1064_energy=1;
            app_get_adc_value( AD2_LASER_1064_INDEX,&e_feedback);
            //DEBUG_PRINTF("energe=%.1f\r\n",sEnvParam.laser_1064_energy);
          }
          #endif
        }
      }
      else //if(recKeyMessage!=key_jt_long_press)
      {
        if(recKeyMessage==key_jt_release&&sGenSta.laser_run_B5_timer_status!=0)
        {
          sGenSta.laser_run_B5_timer_status = 0;
          osTimerStop(laserWorkTimer01Handle);
        }
        if(sGenSta.laser_run_B1_laser_out_status!=0)
        {
          app_laser_pulse_start(LASER_PULSE_STOP,LASER_PULSE_STOP,LASER_PULSE_STOP);
          AD5541A_SetVoltage(0, 4.096);
          sGenSta.laser_run_B1_laser_out_status = 0;
          if(pLaserConfig->proCali==0&&pLaserConfig->treatmentWaterLevel!=0)
          {
            tmc2226_start(!TMC_WATER_OUT_DIR_VALUE,laser_ctr_param.treatmentWaterLevel,CONTINUOUS_STEPS_COUNT);
            osDelay(120);
          }
          tmc2226_stop();
          app_deflate_air_solenoid(DISABLE);
          rgbMessage = RGB_LASER_PREPARE_OK;
          osMessageQueuePut(rgbQueue02Handle,&rgbMessage,0,0);
          DEBUG_PRINTF("stop 1064 stop\r\n");
          sGenSta.laser_param_B456_jt_status = recKeyMessage;
        }
      }
    }
    else
    {
      if(recKeyMessage==key_jt_release)  sGenSta.laser_param_B456_jt_status = key_jt_release;
    }
    laser_close_sem = osSemaphoreAcquire(laserCloseSem05Handle,5);
    if(laser_close_sem==osOK&&sGenSta.laser_run_B0_pro_hot_status!=0)
    {
      osTimerStop(laserWorkTimer01Handle);
      app_laser_pulse_start(LASER_PULSE_STOP,LASER_PULSE_STOP,LASER_PULSE_STOP);
      AD5541A_SetVoltage(0, 4.096);
      tmc2226_stop();
      app_deflate_air_solenoid(DISABLE);
      g_ctr_tx_msg.msg.cmdCode = GWB_3200_REG_RUN_STOP;
      g_ctr_tx_msg.msg.cmdLen  = 1;
      g_ctr_tx_msg.msg.buff[0] = 0;
      gwb_ctr_tx_sta = osMessageQueuePut(jdqGwb3200CtrMessageQueue04Handle,g_ctr_tx_msg.data,NULL,JDQ_RS485_FRAME_MIN_MS);
      if(gwb_ctr_tx_sta!=osOK)
      {
        DEBUG_PRINTF("G3200W reley off fail! resend once\r\n");
        osDelay(JDQ_RS485_FRAME_MIN_MS);
        osMessageQueuePut(jdqGwb3200CtrMessageQueue04Handle,g_ctr_tx_msg.data,NULL,0);
      }
      timeout = 0;
      do
      {
        osDelay(JDQ_RS485_FRAME_MIN_MS);
        timeout+=JDQ_RS485_FRAME_MIN_MS;
        if(timeout>LASER_JDQ_CHARGE_TIMEOUT_MS) break;
      }while(app_jdq_gwb_pwr_flag()!=0);
      jdq_reley_charge(JDG_EX_CONNECT_INTERNAL_LOAD);
      osDelay(JDQ_RS485_FRAME_MIN_MS);
      if(app_jdq_gwb_pwr_flag()==0)
      {
        DEBUG_PRINTF("gwb3200 close ok %f,release voltage\r\n",app_jdq_voltage_monitor());
      }
      else
      {
        DEBUG_PRINTF("gwb3200 close timeout ! resend twice\r\n");
        osMessageQueuePut(jdqGwb3200CtrMessageQueue04Handle,g_ctr_tx_msg.data,NULL,0);
      }
      jdq_reley_internal_load(JDG_INTERNAL_LOAD_CONNECT_TO_GND);
      sGenSta.laser_run_B0_pro_hot_status = 0;
      rgbMessage = RGB_G_STANDBY;
      osMessageQueuePut(rgbQueue02Handle,&rgbMessage,0,0);
      osEventFlagsClear(laserEvent02Handle,EVENTS_LASER_PREPARE_OK_ALL_BITS_MASK);
      timeout = 0;
      do
      {
        //CLEAR JT KEY MESSAGE
        osDelay(50);
        statusJT= osMessageQueueGet(keyJTMessageQueue01Handle,&recKeyMessage,0,10);
        timeout+=10;
        if(timeout>1000) break;
      } while(statusJT==osOK);
      recKeyMessage = NO_KEY_MESSAGE;
    }
    osDelay(5);
  }
  /* USER CODE END laserWorkTask04 */
}

void fastAuxTask05(void *argument)
{
  /* USER CODE BEGIN fastAuxTask05 */
  /* Infinite loop */
  float  treatmentWaterC;
  float  recVoltage,recCurrent;
  app_air_pump_switch(DISABLE);
  for(;;)
  {
    /***********NTC,laser_energe,iBus,Vbus,vBus,air_pump_pressure气泵气压，参数*******************/
    app_get_adc_value(AD1_NTC_INDEX,&sEnvParam.NTC_temprature);//蠕动泵，状态
    app_get_adc_value(AD1_OCP_Ibus_INDEX,&sEnvParam.iBus);
    app_get_adc_value(AD1_24V_VBUS_INDEX,&sEnvParam.vBus);
    /***********气泵管理*******************/
		app_get_adc_value(AD1_AIR_PRESSER_INDEX,&sEnvParam.air_pump_pressure);
    app_get_adc_value(AD1_WATER_PRESSER_INDEX,&sEnvParam.treatment_water_pressure);
		app_air_pump_manage(laser_ctr_param.airPressureLevel);
		/***********更新激光状态*******************/
		app_fresh_laser_status_param();
    osDelay(10);
  }
  /* USER CODE END fastAuxTask05 */
}

void hmiAppTask06(void *argument)
{
  /* USER CODE BEGIN hmiAppTask06 */
  /* Infinite loop */
  //osDelay(13000);
  uint16_t send_music_num = MUSIC_SYS_ON;
  osMessageQueuePut(musicQueue03Handle,&send_music_num,0,100);
  u_sys_param.sys_config_param.synchronousFlag=0;
  uint32_t syncTimeOutS=0;
  for(;;)
  {
    while(u_sys_param.sys_config_param.synchronousFlag!=3)
    {
      if(HAL_GetTick()>17000)
      {
        syncTimeOutS++;
        DEBUG_PRINTF(" synchronous req=%d\r\n",syncTimeOutS);
        app_hmi_sysnc_req();
      }
      if(syncTimeOutS>5)
      {
        DEBUG_PRINTF("sync fail use local paramete\r\n");
        u_sys_param.sys_config_param.synchronousFlag = 3;
      }
      osDelay(1000);
    }
    osStatus_t status = osSemaphoreAcquire(hmiCanBusIdleSem06Handle,HMI_CAN_FRAME_DELAY_TIME);
    if(status==osOK)
    {
      osDelay(HMI_CAN_FRAME_DELAY_TIME);
    }
    app_sys_genaration_status_manage();
    sGenSta.genaration_io_status = osEventFlagsGet(auxStatusEvent01Handle);
    app_hmi_report_status(&sGenSta);
		osDelay(1);
  }
  /* USER CODE END hmiAppTask06 */
}

void canReceiveTask07(void *argument)
{
  /* USER CODE BEGIN canReceiveTask07 */
  /* Infinite loop */
  uint16_t peekLen=0;
  uint8_t buff[8];
  uint32_t Identifier;
  uint16_t len;
  unsigned char fd_canRxBuff[MAX_FDCAN_FRAME_DATALEN+1];//hmi
  unsigned short int  fd_canRxLen = 0;//hmi (initialized to avoid undefined behavior)
  unsigned  int can_rec_timeout=0;
  for(;;)
  {
		/*******************CAN RX-DATA********************/
    can_rec_timeout=osKernelGetTickCount();
    while(FDCAN1_Receive_Msg(buff, &Identifier, &len))
    {
		  if(Identifier==CAN_HMI_ID||Identifier==CAN_BROADCAST_ID)//屏幕
      {
        memcpy(&fd_canRxBuff[fd_canRxLen],buff,8);
        fd_canRxLen+=len;
        fd_canRxLen%=(MAX_FDCAN_FRAME_DATALEN+1);
        if(fd_canRxLen>7)
        {
          #if 0
          DEBUG_PRINTF("CAN_lcd_receive_pack:\r\n");
          for(int i=0;i<peekLen;i++)
          {
            DEBUG_PRINTF(" %02x",fd_canRxBuff[i]);
          }
          DEBUG_PRINTF(" Len=%d\r\n",peekLen);
          #endif
          peekLen = app_hmi_package_check(fd_canRxBuff,fd_canRxLen);
          if(peekLen!=0)
          {
            osSemaphoreRelease(hmiCanBusIdleSem06Handle);//busy
            if(peekLen<fd_canRxLen)
            {
              uint16_t packLen =  fd_canRxLen-peekLen;
              memcpy(fd_canRxBuff,&fd_canRxBuff[peekLen],packLen);
              fd_canRxLen-=peekLen;
            }
            else  {//buff full!
              fd_canRxLen=0;
            }
          }
        }
      }
      if(osKernelGetTickCount()>can_rec_timeout+HMI_CAN_FRAME_DELAY_TIME) break;
    }
    /*****************激光指示灯***********************/
    if(laser_ctr_param.ledLightLevel!=0)
    {
      if(sGenSta.laser_run_B3_laser_pilot_lamp_status==0)
      {
        app_auxiliary_bulb_pwm(laser_ctr_param.ledLightLevel,ENABLE);
        sGenSta.laser_run_B3_laser_pilot_lamp_status=1;
      }
    }
    else
    {
      if(sGenSta.laser_run_B3_laser_pilot_lamp_status!=0)
      {
        app_auxiliary_bulb_pwm(0,DISABLE);
        sGenSta.laser_run_B3_laser_pilot_lamp_status = 0;
      }
    }
   	osDelay(10);
  }
  /* USER CODE END canReceiveTask07 */
}

void powerOffTask08(void *argument)
{
  /* USER CODE BEGIN powerOffTask08 */
  /* Infinite loop */
  for(;;)
  {
    osStatus_t status = osSemaphoreAcquire(powerOffBinarySem02Handle,portMAX_DELAY);

    sGenSta.laser_run_B6_close_device_status=1;
    app_hmi_report_status(&sGenSta);
    ge2117_start_up_set(GE2117_STOP_CMD);
		if(app_sys_param_save_data()==0)
		{
			DEBUG_PRINTF(" sys param save ok\r\n");
		}
    app_beep_pwm(music_tab_c[1],50);
    HAL_TIMEx_PWMN_Start(&htim15,TIM_CHANNEL_1);
    HAL_Delay(500);
    app_beep_pwm(0,0);
    HAL_Delay(1000);
		app_mcu_power_switch(DISABLE);
		DEBUG_PRINTF("DEVICE POWER OFF\r\n");
		while(1)
		{
			DEBUG_PRINTF("please release power key\r\n");
			HAL_Delay(1000);
      #ifdef IWDG_USED
      HAL_IWDG_Refresh(&hiwdg1);
      #endif
		}
   //osDelay(1);
  }
  /* USER CODE END powerOffTask08 */
}

void laserProhotTask09(void *argument)
{
  /* USER CODE BEGIN laserProhotTask09 */
  /* Infinite loop */
  uint32_t timeout;
	uint16_t rgbMessage=1;
  uint16_t laser_freq,laser_Voltage;
	uint8_t local_proHotCtr=0;
	float local_f = 1.0,l_jdq_set_voltage,l_jdq_set_current;
  float outVoltage;
  U_G3200W_CTR_MESSAGE u_g3200w_ctr_tx_message;
  osStatus_t gwb_ctr_tx_status;
  unsigned short int temp_int;
  for(;;)
  {
		osStatus_t sta = osSemaphoreAcquire(laserPrapareReqSem03Handle,portMAX_DELAY);
		local_proHotCtr =	laser_ctr_param.proHotCtr;
		laser_freq = laser_ctr_param.laserFreq;
		laser_Voltage = app_laser_1064_energe_to_voltage(laser_ctr_param.laserEnerge);
    local_f =laser_Voltage*1.0;
    timeout = 0;
    do
    {
      osDelay(JDQ_RS485_FRAME_MIN_MS);
      timeout+=JDQ_RS485_FRAME_MIN_MS;
    }while(u_sys_param.sys_config_param.synchronousFlag!=3&&timeout<LASER_JDQ_CHARGE_TIMEOUT_MS);
    if(local_proHotCtr!=0)
    {
      outVoltage = app_jdq_voltage_monitor();
      //limit charge current
      jdq_reley_charge(JDG_EX_CONNECT_INTERNAL_LOAD);
      if(outVoltage>local_f+5.0)
      { // release voltage
        osDelay(JDQ_RS485_FRAME_MIN_MS);
        jdq_reley_internal_load( JDG_INTERNAL_LOAD_CONNECT_TO_GND);
      }
      timeout = 0;
      do
      {
        osDelay(JDQ_RS485_FRAME_MIN_MS);
        timeout+=JDQ_RS485_FRAME_MIN_MS;
        outVoltage = app_jdq_voltage_monitor();
        if(outVoltage<local_f+5.0) break;
      }while (timeout<LASER_JDQ_CHARGE_TIMEOUT_MS);
      osDelay(JDQ_RS485_FRAME_MIN_MS);
      jdq_reley_internal_load(JDG_INTERNAL_LOAD_CONNECT_TO_160V);
      osDelay(JDQ_RS485_FRAME_MAX_DELAY_MS);
      u_g3200w_ctr_tx_message.msg.cmdCode = GWB_3200_REG_RUN_STOP;
      u_g3200w_ctr_tx_message.msg.cmdLen=1;
      u_g3200w_ctr_tx_message.msg.buff[0]=1;
      gwb_ctr_tx_status = osMessageQueuePut(jdqGwb3200CtrMessageQueue04Handle,u_g3200w_ctr_tx_message.data,NULL,JDQ_RS485_FRAME_MIN_MS);
      if(gwb_ctr_tx_status!=osOK)
      {
        DEBUG_PRINTF("GWB3200W reley on fail!resend once\r\n");
        osDelay(JDQ_RS485_FRAME_MAX_DELAY_MS);
        osMessageQueuePut(jdqGwb3200CtrMessageQueue04Handle,u_g3200w_ctr_tx_message.data,NULL,0);
      }
      timeout=0;
      do
      {  //等待重启
        osDelay(JDQ_RS485_FRAME_MIN_MS);
        timeout+=JDQ_RS485_FRAME_MIN_MS;
        if(timeout>(LASER_JDQ_CHARGE_TIMEOUT_MS>>2))
        {
          DEBUG_PRINTF("GWB3200W reley on timeout restart!\r\n");
          u_g3200w_ctr_tx_message.msg.cmdCode=GWB_3200_REG_RUN_STOP;
          u_g3200w_ctr_tx_message.msg.cmdLen=1;
          u_g3200w_ctr_tx_message.msg.buff[0]=1;
          gwb_ctr_tx_status= osMessageQueuePut(jdqGwb3200CtrMessageQueue04Handle,u_g3200w_ctr_tx_message.data,NULL,JDQ_RS485_FRAME_MIN_MS);
          if(gwb_ctr_tx_status!=osOK)
          {
            DEBUG_PRINTF("GWB3200W reley on fail!resend once\r\n");
            osDelay(JDQ_RS485_FRAME_MAX_DELAY_MS);
            osMessageQueuePut(jdqGwb3200CtrMessageQueue04Handle,u_g3200w_ctr_tx_message.data,NULL,0);
          }
          break;
        }
      }while(app_jdq_gwb_pwr_flag()==0);
      osDelay(2*JDQ_RS485_FRAME_MIN_MS);
      u_g3200w_ctr_tx_message.msg.cmdCode = GWB_3200_REG_SET_VOLTAGE_CURRENT;
      u_g3200w_ctr_tx_message.msg.cmdLen=4;
      temp_int = (unsigned short int)(local_f*100);
      u_g3200w_ctr_tx_message.msg.buff[0]=(temp_int>>8)&0xFF;
      u_g3200w_ctr_tx_message.msg.buff[1]=temp_int&0xFF;
      temp_int = (unsigned short int)(LASER_JDQ_CHARGE_CURRENT_F*100);
      u_g3200w_ctr_tx_message.msg.buff[2]=(temp_int>>8)&0xFF;
      u_g3200w_ctr_tx_message.msg.buff[3]=temp_int&0xFF;
      gwb_ctr_tx_status= osMessageQueuePut(jdqGwb3200CtrMessageQueue04Handle,u_g3200w_ctr_tx_message.data,NULL,JDQ_RS485_FRAME_MIN_MS);
      if(gwb_ctr_tx_status==osOK)
      {
        DEBUG_PRINTF("GWB3200W set  vol=%.1fV  charge cSet=%.1f \r\n",local_f,LASER_JDQ_CURRENT_LIMIT_F);
      }
      else
      {
        DEBUG_PRINTF("GWB3200W set vol and current fail!resend once\r\n");
        osDelay(JDQ_RS485_FRAME_MAX_DELAY_MS);
        osMessageQueuePut(jdqGwb3200CtrMessageQueue04Handle,u_g3200w_ctr_tx_message.data,NULL,0);
      }//charge
      osDelay(JDQ_RS485_FRAME_MAX_DELAY_MS);
      timeout = 0;
      do
      {
        osDelay(JDQ_RS485_FRAME_MAX_DELAY_MS);
        timeout+=JDQ_RS485_FRAME_MAX_DELAY_MS;
        outVoltage = app_jdq_voltage_monitor();
        l_jdq_set_voltage = app_jdq_get_set_vbus()*0.01;
        if(outVoltage>50.0) jdq_reley_charge(JDG_EX_CONNECT_TO_160V);
        if(timeout>LASER_JDQ_CHARGE_TIMEOUT_MS)
        {
          DEBUG_PRINTF("charge time out fail! exit prohot\r\n");
          break;
        }
        DEBUG_PRINTF("charge jdq V=%f set=%f \r\n",outVoltage,l_jdq_set_voltage);
      }while(outVoltage+5.0<local_f);//90% voltage
      if(l_jdq_set_voltage!=JDQ_PWR_GWB_3200W_ERROR_FLAG&&outVoltage+5.0>=local_f)
      {//charge ok set to current limit
        u_g3200w_ctr_tx_message.msg.cmdCode = GWB_3200_REG_SET_VOLTAGE_CURRENT;
        u_g3200w_ctr_tx_message.msg.cmdLen=4;
        temp_int = (unsigned short int)(local_f*100);
        u_g3200w_ctr_tx_message.msg.buff[0]=(temp_int>>8)&0xFF;
        u_g3200w_ctr_tx_message.msg.buff[1]=temp_int&0xFF;
        if(laser_ctr_param.laserType==0&&laser_ctr_param.ctrTestMode==0)
        {
          temp_int = (unsigned short int)(LASER_JDQ_CURRENT_LIMIT_F*100);
        }
        else
        {
          temp_int = (unsigned short int)((LASER_JDQ_CURRENT_LIMIT_F+0.6)*100);//high freq
        }
        u_g3200w_ctr_tx_message.msg.buff[2]=(temp_int>>8)&0xFF;
        u_g3200w_ctr_tx_message.msg.buff[3]=temp_int&0xFF;
        gwb_ctr_tx_status= osMessageQueuePut(jdqGwb3200CtrMessageQueue04Handle,u_g3200w_ctr_tx_message.data,NULL,JDQ_RS485_FRAME_MIN_MS);
        if(gwb_ctr_tx_status==osOK)
        {
          DEBUG_PRINTF("GWB3200W set vol=%.1fV cSet=%.1fA \r\n",local_f,LASER_JDQ_CURRENT_LIMIT_F);
        }
        else
        {
          DEBUG_PRINTF("GWB3200W set vol and current fail!resend once\r\n");
          osDelay(JDQ_RS485_FRAME_MAX_DELAY_MS);
          osMessageQueuePut(jdqGwb3200CtrMessageQueue04Handle,u_g3200w_ctr_tx_message.data,NULL,0);
        }
        DEBUG_PRINTF("charge ok jdq—v%f %d timeMs=%d\r\n",outVoltage,laser_Voltage,timeout);
        rgbMessage = RGB_LASER_PREPARE_OK;
        osMessageQueuePut(rgbQueue02Handle,&rgbMessage,0,0);
        sGenSta.laser_run_B0_pro_hot_status = 1;
        sGenSta.laser_run_B5_timer_status = 1;//wait jt release
        osEventFlagsSet(laserEvent02Handle,EVENTS_LASER_1064_PREPARE_OK_BIT|EVENTS_LASER_JT_ENABLE_BIT);
      }
      else
      {
        DEBUG_PRINTF("charge fail jdq—v%f %d \r\n",outVoltage,laser_Voltage);
        sGenSta.laser_run_B0_pro_hot_status = 0;
        u_g3200w_ctr_tx_message.msg.cmdCode = GWB_3200_REG_RUN_STOP;
        u_g3200w_ctr_tx_message.msg.cmdLen  = 1;
        u_g3200w_ctr_tx_message.msg.buff[0] = 0;
        gwb_ctr_tx_status= osMessageQueuePut(jdqGwb3200CtrMessageQueue04Handle,u_g3200w_ctr_tx_message.data,NULL,JDQ_RS485_FRAME_MIN_MS);
        if(gwb_ctr_tx_status!=osOK)
        {
          DEBUG_PRINTF("GWB3200W reley off fail!resend once\r\n");
          osDelay(JDQ_RS485_FRAME_MAX_DELAY_MS);
          osMessageQueuePut(jdqGwb3200CtrMessageQueue04Handle,u_g3200w_ctr_tx_message.data,NULL,0);
        }
        jdq_reley_internal_load(JDG_INTERNAL_LOAD_CONNECT_TO_GND);
        osDelay(JDQ_RS485_FRAME_MIN_MS);
        jdq_reley_charge(JDG_EX_CONNECT_INTERNAL_LOAD);
      }
    }
    else
    {
      if(sGenSta.laser_run_B0_pro_hot_status != 0) osSemaphoreRelease(laserCloseSem05Handle);
    }
		osDelay(1);
  }
  /* USER CODE END laserProhotTask09 */
}

void ge2117ManageTask10(void *argument)
{
  /* USER CODE BEGIN ge2117ManageTask10 */

  /* Infinite loop */
  uint32_t local_time100mS,g_timeout,local_timeS;
  unsigned char local_water_preapare_flag=0;
  local_time100mS = 0;
  local_timeS=0;//
  //float k0_cool_temprature;
  max_31865_pt1000();
  osDelay(200);
  for(;;)
  {
    osDelay(100);
    if(laser_ctr_param.air_water_prepare_ctr!=local_water_preapare_flag)
    {
      local_water_preapare_flag=laser_ctr_param.air_water_prepare_ctr;
      app_treatment_water_prepare(&local_water_preapare_flag,100);
    }
    float temp_t_f = Get_pt_tempture();
    sEnvParam.eth_k1_temprature = temp_t_f;
    sEnvParam.eth_k2_temprature = temp_t_f;
    local_time100mS++;
    if(local_time100mS>9)
    {
      local_timeS++;
      local_time100mS=0;
      if(sEnvParam.eth_k1_temprature>ERR_LOW_TEMPRATURE_LASER&&sEnvParam.eth_k1_temprature<ERR_HIGH_TEMPRATURE_LASER)
      {
        app_ge2117_gp_ctr(sEnvParam.eth_k1_temprature,local_timeS);
      }
      else
      {
        app_ge2117_gp_ctr(u_sys_param.sys_config_param.cool_temprature_target*0.1,local_timeS);
      }
    }
    if(sEnvParam.eth_k1_temprature>ERR_LOW_TEMPRATURE_LASER&&sEnvParam.eth_k1_temprature<ERR_HIGH_TEMPRATURE_LASER)
    {
      app_circle_water_PTC_manage(sEnvParam.eth_k1_temprature,local_time100mS);
    }
    else
    {
      app_circle_water_PTC_manage(u_sys_param.sys_config_param.cool_temprature_target*0.1,local_time100mS);//stop
    }
  }
  /* USER CODE END ge2117ManageTask10 */
}

void musicTask11(void *argument)
{
  /* USER CODE BEGIN musicTask11 */
  /* Infinite loop */
  uint16_t music_num=0;
  for(;;)
  {
    osMessageQueueGet(musicQueue03Handle,&music_num,0,portMAX_DELAY);
    app_buzz_music(music_num,50);
		osDelay(10);
  }
  /* USER CODE END musicTask11 */
}

void jdqGWB3200wTask12(void *argument)
{
  /* USER CODE BEGIN jdqGWB3200wTask12 */
  /* Infinite loop */
  uint32_t timeout,jdq_geb_hearttimeout=0;
  unsigned char recBuff[8]={0};
  U_G3200W_CTR_MESSAGE u_g3200w_ctr_message;
  osTimerStart(jdqHeart100msTimer04Handle,JDQ_RS485_FRAME_MIN_MS);
  for(;;)
  {
    osDelay(20);
    unsigned char  reclen=app_jdq_rs485_check_gwb3200_rec_package();
    if(reclen==0)
    {
      jdq_geb_hearttimeout+=20;
      if(jdq_geb_hearttimeout>SYS_1_MINUTES_TICK)
      {
        jdq_geb_hearttimeout=0;
        app_jdq_clear_pwr_sta();
        DEBUG_PRINTF("jdq disconnect! \r\n");
        if(sGenSta.laser_run_B0_pro_hot_status!=0) {
          osSemaphoreRelease(laserCloseSem05Handle);
          DEBUG_PRINTF("exit prohot\r\n");
        }
      }
    }
    else jdq_geb_hearttimeout = 0;
    osStatus_t jdq_sta = osSemaphoreAcquire(jdqHeart100msBinarySem05Handle,0);
    if(jdq_sta==osOK)
    {
      osStatus_t gwb_status = osMessageQueueGet(jdqGwb3200CtrMessageQueue04Handle,u_g3200w_ctr_message.data,NULL,0);
      if(gwb_status==osOK)
      {
        if(u_g3200w_ctr_message.msg.cmdCode==GWB_3200_REG_VOLTAGE_CURRENT_DISPLAY)
        {
          app_jdq_bus_get_v_c_req();
        }
        else if( u_g3200w_ctr_message.msg.cmdCode==GWB_3200_REG_RUN_STOP)
        {
          unsigned char cmd = u_g3200w_ctr_message.msg.buff[0];
          app_jdq_bus_power_on_off(cmd);
        }
        else if(u_g3200w_ctr_message.msg.cmdCode==GWB_3200_REG_SET_VOLTAGE_CURRENT)
        {
          float  vSet =( u_g3200w_ctr_message.msg.buff[0]<<8|u_g3200w_ctr_message.msg.buff[1])*0.01;
          float  cSet =( u_g3200w_ctr_message.msg.buff[2]<<8|u_g3200w_ctr_message.msg.buff[3])*0.01;
          app_jdq_bus_vol_current_set(vSet,cSet);
        }
      }
      else
      {
        app_jdq_bus_get_v_c_req();
      }
    }
  }
  /* USER CODE END jdqGWB3200wTask12 */
}

/* LaserWorkTimerCallback01 function */
void LaserWorkTimerCallback01(void *argument)
{
  /* USER CODE BEGIN LaserWorkTimerCallback01 */
  uint16_t send_music_num = MUSIC_SHORT_PROMT;
  if(sGenSta.laser_run_B0_pro_hot_status!=0) osMessageQueuePut(musicQueue03Handle,&send_music_num,0,0);
  sGenSta.laser_run_B5_timer_status=1;
  /* USER CODE END LaserWorkTimerCallback01 */
}

/* cleanWaterCallback02 function */
void cleanWaterCallback02(void *argument)
{
  /* USER CODE BEGIN cleanWaterCallback02 */
  tmc2226_stop();
  /* USER CODE END cleanWaterCallback02 */
}

/* tmcMaxRunTimesCallback03 function */
void tmcMaxRunTimesCallback03(void *argument)
{
  /* USER CODE BEGIN tmcMaxRunTimesCallback03 */
  tmc2226_stop();
  /* USER CODE END tmcMaxRunTimesCallback03 */
}

/* jdqHeart100msCallback04 function */
void jdqHeart100msCallback04(void *argument)
{
  /* USER CODE BEGIN jdqHeart100msCallback04 */
  static unsigned int aux_heart_count = 0;
  osSemaphoreRelease(jdqHeart100msBinarySem05Handle);
  aux_heart_count+=100;
  if(aux_heart_count>=1000){
    aux_heart_count=0;
    osSemaphoreRelease(aux1SHeartBinarySem06Handle);
  }
  #if 0
  static unsigned char beepHeart;
  beepHeart++;
  if(sGenSta.laser_run_B1_laser_out_status!=0)
  {
    if(u_sys_param.sys_config_param.beep!=0&&beepHeart>5)
    {
      beepHeart=0;
      uint16_t s_music_num = MUSIC_LASER_WORK;
      osMessageQueuePut(musicQueue03Handle,&s_music_num,0,0);
    }
  }
  #endif
  /* USER CODE END jdqHeart100msCallback04 */
}

/* USER CODE BEGIN Application */
/**
  * @brief  EXTI line detection callback.
  * @param  GPIO_Pin: Specifies the port pin connected to correspon
  * ding EXTI line.
  * @retval None
  */
 void HAL_GPIO_EXTI_Callback(uint16_t GPIO_Pin)
 {
  if(GPIO_Pin==FAN1_COUNT_in_Pin)
  {
    app_fan_feed_count(1);
  }
  if(GPIO_Pin==LASER_1064_COUNT_in_Pin)
  {
    //counter=clock/u_sys_param.sys_config_param.laser_pulse_width_us;
    //__HAL_TIM_SetAutoreload(&htim5,counter-1);
    //HAL_TIM_Base_Start_IT(&htim5);//光信号触发脉宽
    if(laser_ctr_param.lowEnergeMode==0) pulse_adc_start(MAX_AD2_ENERGE_BUFF_LENGTH);
  }
  #ifdef ONE_WIRE_BUS_JT_SLAVE
  if(GPIO_Pin==FOOT_SWITCH_IN_Pin)
  {
    owb_dq_edge_callback();
  }
  #endif
 }
 /************************************************************************//**
  * @brief 系统一般状态信号管理
  * @param 无
  * @note   周期性更新事件正常标志
  * @retval 无
  *****************************************************************************/
void app_sys_genaration_status_manage(void)
{ //高压电磁阀
  if(app_get_io_status(In1_high_voltage_solenoid)==SUCCESS)
  {
    osEventFlagsSet(auxStatusEvent01Handle,EVENTS_AUX_STATUS_IO1_BIT);
  }
  else
  {
    osEventFlagsClear(auxStatusEvent01Handle,EVENTS_AUX_STATUS_IO1_BIT);
  }
  #if 0
  //堵气阀
  if(app_get_io_status(In2_deflate_air_solenoid)==SUCCESS)
  {
    osEventFlagsSet(auxStatusEvent01Handle,EVENTS_AUX_STATUS_IO2_BIT);
  }
  else
  {
    osEventFlagsClear(auxStatusEvent01Handle,EVENTS_AUX_STATUS_IO2_BIT);
  }
  //泄气阀
  if(app_get_io_status(In3_chocke_air_solenoid)==SUCCESS)
  {
    osEventFlagsSet(auxStatusEvent01Handle,EVENTS_AUX_STATUS_IO3_BIT);
  }
  else
  {
    osEventFlagsClear(auxStatusEvent01Handle,EVENTS_AUX_STATUS_IO3_BIT);
  }
  #else
  //气阀 ,不再使用
  osEventFlagsSet(auxStatusEvent01Handle,EVENTS_AUX_STATUS_IO2_BIT);
  osEventFlagsSet(auxStatusEvent01Handle,EVENTS_AUX_STATUS_IO3_BIT);
  #endif
   //环境温度报警
  if(app_get_io_status(In4_enviroment_tmprature_alert)==SUCCESS)
  {
    osEventFlagsSet(auxStatusEvent01Handle,EVENTS_AUX_STATUS_IO4_BIT);
  }
  else
  {
    osEventFlagsClear(auxStatusEvent01Handle,EVENTS_AUX_STATUS_IO4_BIT);
  }	//气泵过热报警
	if(app_get_io_status(In5_h_air_error)==SUCCESS)
	{
    osEventFlagsSet(auxStatusEvent01Handle,EVENTS_AUX_STATUS_IO5_BIT);
	}
	else
  {
    osEventFlagsClear(auxStatusEvent01Handle,EVENTS_AUX_STATUS_IO5_BIT);
  }
	//气泵气压过高信号报警,低报警
	if(app_get_io_status(In6_Hyperbaria_OFF_Signal)==SUCCESS)
	{
    osEventFlagsSet(auxStatusEvent01Handle,EVENTS_AUX_STATUS_IO6_BIT);
	}
	else
  {
    osEventFlagsClear(auxStatusEvent01Handle,EVENTS_AUX_STATUS_IO6_BIT);
  }
  //治疗出水OK信号
	if(app_get_io_status(In7_water_ready_ok)==SUCCESS)
	{
    osEventFlagsSet(auxStatusEvent01Handle,EVENTS_AUX_STATUS_IO7_BIT);
	}
	else
  {
    osEventFlagsClear(auxStatusEvent01Handle,EVENTS_AUX_STATUS_IO7_BIT);
  }
  //水循环就绪信号
	if(app_get_io_status(In8_water_circle_ok)==SUCCESS)
	{
    osEventFlagsSet(auxStatusEvent01Handle,EVENTS_AUX_STATUS_IO8_BIT);
  }
	else
  {
    osEventFlagsClear(auxStatusEvent01Handle,EVENTS_AUX_STATUS_IO8_BIT);
  }
  if(sEnvParam.NTC_temprature>MAX_TMC2226_NTC_TEMPRATURE)//过热
  {
    osEventFlagsClear(auxStatusEvent01Handle,EVENTS_AUX_STATUS_9_NTC_BIT);
  }
  else
  {
    osEventFlagsSet(auxStatusEvent01Handle,EVENTS_AUX_STATUS_9_NTC_BIT);
  }
  if(sEnvParam.iBus<MAX_IBUS_MA)//<10A
  {
    osEventFlagsSet(auxStatusEvent01Handle,EVENTS_AUX_STATUS_10_IBUS_BIT);
  }
  else
  {
    osEventFlagsClear(auxStatusEvent01Handle,EVENTS_AUX_STATUS_10_IBUS_BIT);
  }
  if(sEnvParam.vBus>MIN_VBUS_MV)
  {
    osEventFlagsSet(auxStatusEvent01Handle,EVENTS_AUX_STATUS_11_VBUS_BIT);
  }
  else
  {
    osEventFlagsClear(auxStatusEvent01Handle,EVENTS_AUX_STATUS_11_VBUS_BIT);
  }
  if(sEnvParam.eth_k1_temprature>ERR_LOW_TEMPRATURE_LASER&&sEnvParam.eth_k1_temprature<ERR_HIGH_TEMPRATURE_LASER)
  {
    osEventFlagsSet(auxStatusEvent01Handle,EVENTS_AUX_STATUS_12_K1_TEMPRATURE_BIT);
  }
  else
  {
    osEventFlagsClear(auxStatusEvent01Handle,EVENTS_AUX_STATUS_12_K1_TEMPRATURE_BIT);
  }
  osEventFlagsSet(auxStatusEvent01Handle,EVENTS_AUX_STATUS_13_K2_TEMPRATURE_BIT);   //未使用
  //紧急开关
  if(app_get_io_status(In9_emergency_ok)==SUCCESS)
  {
    osEventFlagsSet(auxStatusEvent01Handle,EVENTS_AUX_STATUS_14_EMERGENCY_KEY_BIT);
  }
  else
  {
    osEventFlagsClear(auxStatusEvent01Handle,EVENTS_AUX_STATUS_14_EMERGENCY_KEY_BIT);
    if(laser_ctr_param.proHotCtr!=0&&sGenSta.laser_run_B0_pro_hot_status!=0)
    {
      laser_ctr_param.proHotCtr=0;
      DEBUG_PRINTF("emergency!\r\n");
      osSemaphoreRelease(laserCloseSem05Handle);
    }
  }
  //治疗水瓶水位
  if(HAL_GPIO_ReadPin(TREATMENT_WATER_DEPTH_in_GPIO_Port,TREATMENT_WATER_DEPTH_in_Pin)==GPIO_PIN_RESET)
  {//正常
    sEnvParam.treatment_water_depth = 1;
    osEventFlagsSet(auxStatusEvent01Handle,EVENTS_AUX_STATUS_15_TREATMEAT_WATER_DEPTH_BIT);
  }
  else {
    osEventFlagsClear(auxStatusEvent01Handle,EVENTS_AUX_STATUS_15_TREATMEAT_WATER_DEPTH_BIT);
    sEnvParam.treatment_water_depth = 0;  //缺水
  }
  #if 1
  //IO型循环水位
  if(app_get_cool_water_depth()==SUCCESS)
  {
    if(u_sys_param.sys_config_param.cool_water_depth_low<u_sys_param.sys_config_param.cool_water_depth_high)
    {
      sEnvParam.cool_water_depth = u_sys_param.sys_config_param.cool_water_depth_high;
    }
    else
    {
      sEnvParam.cool_water_depth = u_sys_param.sys_config_param.cool_water_depth_low+1;
    }
  }
  else  sEnvParam.cool_water_depth=u_sys_param.sys_config_param.cool_water_depth_low;
  #else
   //sEnvParam.cool_water_depth = 100;//mcp
  sEnvParam.cool_water_depth   = app_mcp61_c_value()*10;//real depth =0.1pf*10
  #endif
  if( sEnvParam.cool_water_depth>u_sys_param.sys_config_param.cool_water_depth_low)
  {
    osEventFlagsSet(auxStatusEvent01Handle,EVENTS_AUX_STATUS_16_COOL_WATER_BIT);
  }
  else
  {//缺水
    osEventFlagsClear(auxStatusEvent01Handle,EVENTS_AUX_STATUS_16_COOL_WATER_BIT);
  }
  //DEBUG_PRINTF("IO8~1=%d%d%d%d%d%d%d%d\r\n" ,sGenSta.water_circle_ok_status,sGenSta.water_ready_ok_status,\
    sGenSta.Hyperbaria_OFF_Signal_staus,sGenSta.h_air_error_status ,sGenSta.enviroment_tmprature_alert_status,\
    sGenSta.chocke_air_solenoid_status, sGenSta.deflate_air_solenoid_status,sGenSta.high_voltage_solenoid_status);
}
/************************************************************************//**
  * @brief 计算设备ID
  * @param 无
  * @note
  * @retval
  *****************************************************************************/
unsigned  int app_get_cali_devid(void)
{
	unsigned  int id;
	unsigned char buf[12];//96bit
	buf[0]=HAL_GetUIDw0()&0xFF;
	buf[1]=(HAL_GetUIDw0()>>8)&0xFF;
	buf[2]=(HAL_GetUIDw0()>>16)&0xFF;
	buf[3]=(HAL_GetUIDw0()>>24)&0xFF;

	buf[4]=HAL_GetUIDw1()&0xFF;
	buf[5]=(HAL_GetUIDw1()>>8)&0xFF;
	buf[6]=(HAL_GetUIDw1()>>16)&0xFF;
	buf[7]=(HAL_GetUIDw1()>>24)&0xFF;

	buf[8]=HAL_GetUIDw2()&0xFF;
	buf[9]=(HAL_GetUIDw2()>>8)&0xFF;
	buf[10]=(HAL_GetUIDw2()>>16)&0xFF;
	buf[11]=(HAL_GetUIDw2()>>24)&0xFF;
	id =  crc32_MPEG(buf,12);
	return id;
}
/************************************************************************//**
  * @brief 使用默认系统参数
  * @param 无
  * @note
  * @retval
  *****************************************************************************/
void app_set_default_sys_config_param(void)
{
	u_sys_param. sys_config_param.synchronousFlag = 0;
  if(u_sys_param. sys_config_param.equipmentId==0||u_sys_param. sys_config_param.equipmentId==0xFFFFFFFF)
  {
	  u_sys_param. sys_config_param.equipmentId = app_get_cali_devid();//默认参数
  }
  u_sys_param. sys_config_param.jtId=0;
  u_sys_param. sys_config_param.jt_status=1;
  u_sys_param. sys_config_param.cool_temprature_low=210;//21.0f
  u_sys_param. sys_config_param.cool_temprature_target=230;//23.0f
  u_sys_param. sys_config_param.cool_temprature_high=280;//28.0f
  u_sys_param. sys_config_param.photodiod_low=0;//50mj
  u_sys_param. sys_config_param.photodiod_mid=99;//100mJ
  u_sys_param. sys_config_param.photodiod_high=200;//205mJ
  u_sys_param. sys_config_param.laser_pulse_count=0;
  u_sys_param. sys_config_param.laser_use_timeS=0;
  u_sys_param. sys_config_param.RDB_use_timeS=0;
  u_sys_param. sys_config_param.laser_pulse_width_us=120;
  u_sys_param. sys_config_param.treatment_water_depth_high=151;//15.1pf
  u_sys_param. sys_config_param.treatment_water_depth_low=87;//8.7pF
  u_sys_param. sys_config_param.cool_water_depth_high=167;//16.7pf
  u_sys_param. sys_config_param.cool_water_depth_low=52;//5.2
  u_sys_param. sys_config_param.air_low_pressure=140;
  u_sys_param. sys_config_param.air_mid_pressure=170;
  u_sys_param. sys_config_param.air_high_pressure=190;
  u_sys_param. sys_config_param.t_water_low=15;//10ml/min
  u_sys_param. sys_config_param.t_water_mid=25;
  u_sys_param. sys_config_param.t_water_high=35;
  u_sys_param. sys_config_param.dit_time_min=5;//5min
  u_sys_param. sys_config_param.clean_time_min=5;
  u_sys_param. sys_config_param.tec_switch=1;
  u_sys_param. sys_config_param.low_freq=60;//MAX60Hz
  u_sys_param. sys_config_param.charge_width_us=180;//180us//
  u_sys_param.sys_config_param.laser_led_light=50;            //）激光指示灯亮度
  u_sys_param.sys_config_param.rgb_light=50;                  //）rgb状态指示灯亮度
  u_sys_param.sys_config_param.beep=50;                       //）音量
  for(uint8_t i=0;i<40;i++)
  {
    u_sys_param. sys_config_param.e_cali[i].energe_cali=2500;
    u_sys_param. sys_config_param.e_cali[i].power_cali=2500;//
  }
  u_sys_param.sys_config_param.checkSum=sumCheck(u_sys_param.data,SYS_LASER_CONFIG_PARAM_LENGTH);//sizeof(SYS_CONFIG_PARAM)-4);
	DEBUG_PRINTF("sys param load failed! load defalut param\r\n");
  memcpy(u_sys_default_param.data,u_sys_param.data,sizeof(SYS_CONFIG_PARAM));

  laser_ctr_param.airPressureLevel=1;
  laser_ctr_param.treatmentWaterLevel=0;
  laser_ctr_param.ledLightLevel=20;
}
/************************************************************************//**
  * @brief 加载本地系统参数
  * @param 无
  * @note
  * @retval
  *****************************************************************************/
  void app_sys_param_load(void)
  {
    unsigned char flag;
    flag = EEPROM_M24C32_Read(EEROM_SYS_PARAM_SAVE_ADDR, u_sys_param.data, sizeof(SYS_CONFIG_PARAM));
    unsigned int sum = sumCheck(u_sys_param.data,SYS_LASER_CONFIG_PARAM_LENGTH);
    if(u_sys_param.sys_config_param.synchronousFlag==EEROM_DATA_ERR_CHECK_FLAG||u_sys_param.sys_config_param.checkSum!=sum)//
    {
      app_set_default_sys_config_param();
      DEBUG_PRINTF("load default sys param\r\n");
    }
    else
    {//check param
      u_sys_param.sys_config_param.synchronousFlag = 0;//请求配置
      if(u_sys_param.sys_config_param.cool_temprature_target>280||u_sys_param.sys_config_param.cool_temprature_target<210)
      {
        u_sys_param.sys_config_param.cool_temprature_target=240;
      }
      memcpy(u_sys_default_param.data,u_sys_param.data,sizeof(SYS_CONFIG_PARAM));
      laser_ctr_param.airPressureLevel=1;
      laser_ctr_param.treatmentWaterLevel=0;
      laser_ctr_param.ledLightLevel=20;
      #if 1
      DEBUG_PRINTF("***************sys param read ok*************************\r\n");
      DEBUG_PRINTF("synchronousFlag=%d\r\n", u_sys_param. sys_config_param.synchronousFlag);
      DEBUG_PRINTF("equipmentId=%x\r\n",u_sys_param. sys_config_param.equipmentId);
      DEBUG_PRINTF("jtId=%d\r\n",u_sys_param. sys_config_param.jtId);
      DEBUG_PRINTF("jt_status=%d\r\n",u_sys_param. sys_config_param.jt_status);
      DEBUG_PRINTF("cool_temprature_low=%.1f℃\r\n",u_sys_param. sys_config_param.cool_temprature_low*0.1);
      DEBUG_PRINTF("cool_temprature_target=%.1f℃\r\n",u_sys_param. sys_config_param.cool_temprature_target*0.1);
      DEBUG_PRINTF("cool_temprature_high=%.1f℃\r\n",u_sys_param. sys_config_param.cool_temprature_high*0.1);

      DEBUG_PRINTF("photodiod_low=%d\r\n",u_sys_param. sys_config_param.photodiod_low);
      DEBUG_PRINTF("photodiod_mid=%d\r\n",u_sys_param. sys_config_param.photodiod_mid);
      DEBUG_PRINTF("photodiod_high=%d\r\n",u_sys_param. sys_config_param.photodiod_high);
      DEBUG_PRINTF("laser_pulse_count=%d\r\n",u_sys_param. sys_config_param.laser_pulse_count);
      DEBUG_PRINTF("laser_use_timeS=%d\r\n",u_sys_param. sys_config_param.laser_use_timeS);
      DEBUG_PRINTF("RDB_use_timeS=%d\r\n",u_sys_param. sys_config_param.RDB_use_timeS);
      DEBUG_PRINTF("laser_pulse_width_us=%d\r\n",u_sys_param. sys_config_param.laser_pulse_width_us);
      DEBUG_PRINTF("treatment_water_depth_high=%.1fr\n",u_sys_param. sys_config_param.treatment_water_depth_high*0.1);
      DEBUG_PRINTF("treatment_water_depth_low=%.1f\r\n",u_sys_param. sys_config_param.treatment_water_depth_low*0.1);
      DEBUG_PRINTF("cool_water_depth_high=%.1f \r\n",u_sys_param. sys_config_param.cool_water_depth_high*0.1);
      DEBUG_PRINTF("cool_water_depth_low=%.1f \r\n",u_sys_param. sys_config_param.cool_water_depth_low*0.1);
      DEBUG_PRINTF("air_low_pressure=%d kPa\r\n",u_sys_param. sys_config_param.air_low_pressure);
      DEBUG_PRINTF("air_mid_pressure=%d kPa\r\n",u_sys_param. sys_config_param.air_mid_pressure);
      DEBUG_PRINTF("air_high_pressure=%d kPa\r\n",u_sys_param. sys_config_param.air_high_pressure);
      DEBUG_PRINTF("t_water_low=%d ml/min\r\n",u_sys_param. sys_config_param.t_water_low);
      DEBUG_PRINTF("t_water_mid=%d ml/min\r\n",u_sys_param. sys_config_param.t_water_mid);
      DEBUG_PRINTF("t_water_high=%d  ml/min\r\n",u_sys_param. sys_config_param.t_water_high);
      DEBUG_PRINTF("dit_time_min=%d  min\r\n",u_sys_param. sys_config_param.dit_time_min);
      DEBUG_PRINTF("clean_time_min=%d  min\r\n",u_sys_param. sys_config_param.clean_time_min);
      DEBUG_PRINTF("tec_switch=%d\r\n",u_sys_param. sys_config_param.tec_switch);
      DEBUG_PRINTF("low_freq=%d\r\n",u_sys_param. sys_config_param.low_freq);
      DEBUG_PRINTF("charge_width_us=%d\r\n",u_sys_param. sys_config_param.charge_width_us);
      DEBUG_PRINTF("laser_led_light=%d\r\n",u_sys_param. sys_config_param.laser_led_light);
      DEBUG_PRINTF("rgb_light=%d\r\n",u_sys_param. sys_config_param.rgb_light);
      DEBUG_PRINTF("beep=%d\r\n",u_sys_param. sys_config_param.beep);
      DEBUG_PRINTF("eCali=%d\r\n",u_sys_param. sys_config_param.e_cali->energe_cali);
      DEBUG_PRINTF("pCali=%d\r\n",u_sys_param. sys_config_param.e_cali->power_cali);
      DEBUG_PRINTF("*******************sys param end*************************\r\n");
      #endif
    }
  }
/************************************************************************//**
  * @brief 系统参数保存到本地
  * @param 无
  * @note
  * @retval
  *****************************************************************************/
 unsigned char app_sys_param_save_data(void)
 {
    unsigned char flag=0;
    if(compare_buff_no_change(u_sys_param.data,u_sys_default_param.data,sizeof(SYS_CONFIG_PARAM))!=HAL_OK)
    {
      u_sys_param.sys_config_param.checkSum = sumCheck(u_sys_param.data,SYS_LASER_CONFIG_PARAM_LENGTH);
      flag = EEPROM_M24C32_Write(EEROM_SYS_PARAM_SAVE_ADDR, u_sys_param.data, sizeof(SYS_CONFIG_PARAM));
    }
    return flag;
 }
 /************************************************************************//**
  * @brief 气泵管理
  * @param air_level 气泵气压等级
  * @note
  * @retval
  *****************************************************************************/
 void app_air_pump_manage(unsigned char air_level)
 {
  uint32_t eventFlag= osEventFlagsGet(auxStatusEvent01Handle);
  unsigned char duty_cali=0,duty;
  float air_pressure=MID_AIR_PUMP_PRESSURE+sEnvParam.air_gzp_enviroment_pressure_kpa;
  if(air_level==1)
  {
    duty=20;
    air_pressure = u_sys_param.sys_config_param.air_low_pressure+sEnvParam.air_gzp_enviroment_pressure_kpa;
    //air_pressure = MIN_AIR_PUMP_PRESSURE+sEnvParam.air_gzp_enviroment_pressure_kpa;
  }
  else if(air_level==3)
  {
    duty=30;
    air_pressure   =  u_sys_param.sys_config_param.air_mid_pressure+sEnvParam.air_gzp_enviroment_pressure_kpa;
    //air_pressure = MAX_AIR_PUMP_PRESSURE+sEnvParam.air_gzp_enviroment_pressure_kpa;
  }
  else if(air_level==2)
  {
    duty=25;
    air_pressure = u_sys_param.sys_config_param.air_high_pressure+sEnvParam.air_gzp_enviroment_pressure_kpa;
    //air_pressure=MID_AIR_PUMP_PRESSURE+sEnvParam.air_gzp_enviroment_pressure_kpa;
  }
  if(air_level!=sGenSta.air_level_status) //= laser_ctr_param.airPressureLevel&&((eventFlag&EVENTS_AUX_STATUS_IO6_BIT)== EVENTS_AUX_STATUS_IO6_BIT)&&sGenSta.laser_run_B0_pro_hot_status!=0)//
  {
    sGenSta.air_level_status=air_level;
    if(sEnvParam.air_gzp_enviroment_pressure_kpa>100.0)
    {
      duty_cali=(sEnvParam.air_pump_pressure-95.0)*100/air_pressure;
      duty_cali%=5;//校准值不超过5%
      app_air_pum_pwm_set(duty-duty_cali);
    }
    else  if(sEnvParam.air_gzp_enviroment_pressure_kpa<90.0)
    {
      duty_cali=(95.0-sEnvParam.air_pump_pressure)*100/air_pressure;
      duty_cali%=5;//校准值不超过5%
      app_air_pum_pwm_set(duty+duty_cali);
    }
    else
    {
      duty_cali = 0;
      app_air_pum_pwm_set(duty);
    }
  }
  #if 1
  //本机取消气瓶
  sGenSta.laser_param_B23_air_pump_pressure_status = 1;
  #else
  if(sEnvParam.air_pump_pressure+10<(MIN_AIR_PUMP_PRESSURE + sEnvParam.air_gzp_enviroment_pressure_kpa) )
  {
    sGenSta.laser_param_B23_air_pump_pressure_status = 0;
  }
  else if(sEnvParam.air_pump_pressure > ( MAX_AIR_PUMP_PRESSURE + sEnvParam.air_gzp_enviroment_pressure_kpa+10) )
  {
    sGenSta.laser_param_B23_air_pump_pressure_status = 2;
  }
  else
  {
    sGenSta.laser_param_B23_air_pump_pressure_status = 1;
  }
  #endif
 }
 /************************************************************************//**
  * @brief 更新状态参数
  * @param 无
  * @note
  * @retval
  *****************************************************************************/
  void app_fresh_laser_status_param(void)
  {
    sGenSta.circle_water_box_temprature  = (char)((int)sEnvParam.eth_k1_temprature);
    sGenSta.treatment_water_level_status = laser_ctr_param.treatmentWaterLevel;
    sGenSta.laser_run_B2_gx_test_status  = laser_ctr_param.ctrTestMode;
  }
  /************************************************************************//**
  * @brief laser
  * @param energe ,能量
  * @note   能量单位mJ
  * @retval  换算后电压100mV
  *****************************************************************************/
  unsigned short int  app_laser_1064_energe_to_voltage(unsigned short int energe)
  {
    unsigned short int ret_vol;
    /* HSM_III_lite
      ret_vol=energe*32+8000;
      if(ret_vol<LASER_1064_MIN_ENERGE_V) ret_vol=LASER_1064_MIN_ENERGE_V;
      if(ret_vol>LASER_1064_MAX_ENERGE_V) ret_vol=LASER_1064_MAX_ENERGE_V;
    */
    ret_vol = LASER_JDQ_VOLTAGE;
    return ret_vol;
  }

 /***************************extern api**********************************************************/
 /************************************************************************//**
  * @brief 给出激光准备信号量
  * @param 无
  * @note
  * @retval
  *****************************************************************************/
void app_laser_preapare_semo(void)
{
  osSemaphoreRelease( laserPrapareReqSem03Handle);
}
/************************************************************************//**
  * @brief 水雾准备
  * @param 无
  * @note
  * @retval
  *****************************************************************************/
 void app_treatment_water_prepare(unsigned char *ctrflag,unsigned int runtimeMs)
 {
    if(*ctrflag!=0)
    {
      tmc2226_start(TMC_WATER_OUT_DIR_VALUE,3,CONTINUOUS_STEPS_COUNT);
      osTimerStart(tmcMaxRunTimer03Handle,20*SYS_1_MINUTES_TICK);
    }
    else
    {
      osTimerStop(tmcMaxRunTimer03Handle);
      tmc2226_stop();
    }
}
  /************************************************************************//**
  * @brief 消毒、清洗指令
  * @param 无
  * @note
  * @retval
  *****************************************************************************/
 void app_t_clean_run_timer(unsigned char *runflag)
 {
    if(*runflag!=0)
    {
      unsigned int runtimeS;
      if(*runflag ==1) runtimeS = u_sys_param.sys_config_param.dit_time_min*SYS_1_MINUTES_TICK;
      else if(*runflag ==2) runtimeS = u_sys_param.sys_config_param.clean_time_min*SYS_1_MINUTES_TICK;
      cleanTimer02Handle = osTimerNew(cleanWaterCallback02, osTimerOnce, NULL, &cleanTimer02_attributes);
      osTimerStart(cleanTimer02Handle,runtimeS);
      tmc2226_start(TMC_WATER_OUT_DIR_VALUE,3,CONTINUOUS_STEPS_COUNT);
    }
    else
    {
      osTimerStop(cleanTimer02Handle);
      tmc2226_stop();
    }
 }
/***************************************************************************//**
 * @brief 数据包检查
 * @param
 * @note  最小包长8字节
 * @return
*******************************************************************************/
unsigned short int app_hmi_package_check(unsigned char* pBuff,unsigned short int buffLen)
{
	  unsigned short int retLen = 0;
    unsigned short i = 0;
    while (i < buffLen)
    {
        // need at least 3 bytes to read header+length
        if (buffLen < i+3)
        {
            retLen = i;
            break;
        }
        if (pBuff[i] == 0x7E && pBuff[i + 1] == 0x7E)
        {
            unsigned short pLen = pBuff[i + 2];
            // basic sanity: minimum packet length (protocol dependent). Use 8 as previous comment suggested.
            if (pLen >= 8)
            {
                // if full packet not yet received, wait for more data
                if ((unsigned int)i + (unsigned int)pLen <= (unsigned int)buffLen)
                {
                    // safe to read CRC bytes now
                    unsigned short crc_read = (unsigned short)pBuff[i + pLen - 4] | ((unsigned short)pBuff[i + pLen - 3] << 8);
                    if (crc_read == crc16Num(pBuff + i, pLen - 4))
                    {
                      HMI_Parse_Data(&pBuff[i], pLen);
                      retLen = pLen + i;
                      i += pLen;
                    }
                    else
                    {
                      i++;
                    }
                }
                else
                {
                  retLen = i;
                  break;
                }
            }
            else
            {
              i++;
            }
        }
        else
        {
          i++;
        }
    }
    if (i == buffLen)
    {
      retLen = i;
    }
    return retLen;
}
/************************************************************************//**
* @brief 蜂鸣器PWM
  * @param delayPai节拍
  * @note
  * @retval
  *****************************************************************************/
 void app_beep_pai_tim(unsigned char delayPai)
 {//1s一个音符，0.25秒一个节拍
  unsigned  int dp;
  dp = (delayPai-30)*75;//125 ;
  osDelay(dp);
 }
/************************************************************************//**
* @brief 蜂鸣器music
  * @param volnum 音量0~100；
  * @note
  * @retval
  *****************************************************************************/
 void app_buzz_music(music_type  music_num,unsigned char volume)
 {
   unsigned int j, vol;
   vol=1;//1低，2，中，3高
   if(music_num==MUSIC_SHORT_PROMT)
   {
      app_beep_pwm(music_tab_c[1],50);
      HAL_TIMEx_PWMN_Start(&htim15,TIM_CHANNEL_1);
      osDelay(300);
      app_beep_pwm(0,0);
      osDelay(300);
   }
   else if(music_num==MUSIC_LONG_PROMT)
   {
      app_beep_pwm(music_tab_c[16],50);
      HAL_TIMEx_PWMN_Start(&htim15,TIM_CHANNEL_1);
      osDelay(1500);
      app_beep_pwm(0,0);
      osDelay(500);
   }
   else if(music_num==MUSIC_TWO_TIGER)
   {
      vol=1;
      app_beep_pwm(50,50);
      HAL_TIMEx_PWMN_Start(&htim15,TIM_CHANNEL_1);
      for(j=0;j<32;j++)
      {
        app_beep_pwm(music_tab_c[music_two_tiger[j*2]*vol],50);
        app_beep_pai_tim(music_two_tiger[2*j+1]);
      }
      app_beep_pwm(0,50);
   }
   else if(music_num==MUSIC_STAR)
   {
      vol=1;
      app_beep_pwm(50,50);
      HAL_TIMEx_PWMN_Start(&htim15,TIM_CHANNEL_1);
      for(j=0;j<42;j++)
      {
        app_beep_pwm(music_tab_c[music_star[j*2]*vol],50);
        app_beep_pai_tim(music_star[2*j+1]);
      }
      app_beep_pwm(0,0);
   }
   else if(music_num==MUSIC_HAPPY)
   {
      vol=2;
      app_beep_pwm(50,50);
      HAL_TIMEx_PWMN_Start(&htim15,TIM_CHANNEL_1);
      for(j=0;j<48;j++)
      {
        app_beep_pwm(music_tab_c[music_happy[2*j]*vol],50);
        app_beep_pai_tim(music_happy[2*j+1]);
      }
      app_beep_pwm(0,0);
   }
   else if(music_num==MUSIC_SYS_ON)
   {
      app_beep_pwm(music_tab_c[6],50);
      HAL_TIMEx_PWMN_Start(&htim15,TIM_CHANNEL_1);
      osDelay(300);
      app_beep_pwm(music_tab_c[16],50);
      osDelay(300);
      app_beep_pwm(music_tab_c[21],50);
      osDelay(400);
      app_beep_pwm(0,0);
   }
   else if(music_num==MUSIC_LASER_WORK)
   {
      if( laser_ctr_param.beep!=0)
      {
        app_beep_pwm(music_tab_c[16],50);
        HAL_TIMEx_PWMN_Start(&htim15,TIM_CHANNEL_1);
        osDelay(200);
        app_beep_pwm(0,0);
      }
   }
   else app_beep_pwm(0,0);
 }
  /************************************************************************//**
  * @brief 激光能量反馈计算
  * @param
  * @note  0.75mA/mW
  * @retval  能量值
  *****************************************************************************/
 unsigned short int app_energe_cali( unsigned int adVoltage )
 {
    static unsigned short int e_value;
    sEnvParam.laser_1064_energy = e_value;
    return e_value;
 }
  /***************************************************************************//**
 * @brief app_jdq_restart
 * @param
 * @note
 * @return
*******************************************************************************/
 void app_jdq_restart(void)
 {
	 jdq_reley_charge(JDG_EX_CONNECT_INTERNAL_LOAD);//
	 osDelay(10);
   jdq_reley_internal_load(JDG_INTERNAL_LOAD_CONNECT_TO_GND);
   osDelay(50);
	 jdq_reley_charge(JDG_EX_CONNECT_TO_160V);//
   osDelay(1000);
 }
 #ifdef JDQ_PWR_GWB_3200W
 /***************************************************************************//**
 * @brief 状态管理
 * @param
 * @note
 * @return
*******************************************************************************/
void app_jdq_gwb3200_status_manage_handle(unsigned  int timeMs)
{
	static unsigned  int heatTime;
  heatTime +=	timeMs;
	if(heatTime>SYS_1_MINUTES_TICK )
	{
		app_jdq_restart();
		heatTime=0;
	}
	else
	{
		app_jdq_bus_get_v_c_req();
	}
}
#endif
 /***************************************************************************//**
 * @brief 能量与电压计算
 * @param energe
 * @note
 * @return 目标Vdac值
*******************************************************************************/
float  app_energe_vdac(unsigned short int energe,unsigned short int pulseWidthUs)
{
  float retVdac;
  if(energe> ENERGE_MAX_VALUE) energe=ENERGE_MAX_VALUE;
  if(energe< ENERGE_MIN_VALUE) energe=ENERGE_MIN_VALUE;
  if(pulseWidthUs<100) pulseWidthUs=100;
  if(pulseWidthUs>230) pulseWidthUs=230;
 //temprature
  float freq_e=1.0;
  float  e_pulse=0;//脉宽补偿
  float  e_T=0;  //温度补偿
  #if 1
  if(laser_ctr_param.laserFreq>50) freq_e=0.924-laser_ctr_param.laserFreq*0.0003;
  else if(laser_ctr_param.laserFreq>30) freq_e=0.949-laser_ctr_param.laserFreq*0.0005;
  else  if(laser_ctr_param.laserFreq>10) freq_e=1-laser_ctr_param.laserFreq*0.0017;
  else  if(laser_ctr_param.laserFreq>=5) freq_e=1.050-0.005*laser_ctr_param.laserFreq;
  else freq_e=1.090-0.009*laser_ctr_param.laserFreq;
  if(sEnvParam.eth_k1_temprature<24.0)
  {
    if(energe<25)
    {
      e_T=+0.10*(24.0-sEnvParam.eth_k1_temprature);//0.90
    }
   else  e_T=+0.06*(24.0-sEnvParam.eth_k1_temprature);//0.90
  }
  else // if(sEnvParam.eth_k1_temprature>=24.0)
  {
    if( sEnvParam.eth_k1_temprature>30)
    {
      e_T=-0.06;//1.08
    }
    else
    {
      e_T=-0.01*(sEnvParam.eth_k1_temprature-24.0);
    }
  }
    e_pulse=(200-pulseWidthUs)*(0.00035);
  #endif
  if(energe<=15)
  {
    retVdac=1.35+((energe)*freq_e*(1.30+e_pulse+e_T)/pulseWidthUs);
  }
  else
  {
    retVdac=1.40+((energe)*freq_e*(1.30+e_pulse+e_T)/pulseWidthUs);
  }
  //校准参数
  if(energe>4)
  {
    if(u_sys_param.sys_config_param.e_cali[(energe/5)-1].energe_cali>2500)
    {
      retVdac+=(u_sys_param.sys_config_param.e_cali[(energe/5)-1].energe_cali-2500)*0.0001;//
    }
    else  retVdac-=(2500-u_sys_param.sys_config_param.e_cali[(energe/5)-1].energe_cali)*0.0001;//
  }
  if(retVdac>DAC_MAX_VOLTAGE_F) retVdac = DAC_MAX_VOLTAGE_F;
  if(retVdac<DAC_MIN_VOLTAGE_F) retVdac = DAC_MIN_VOLTAGE_F;
  return retVdac;
}
 /************************************************************************//**
  * @brief 任务状态异常
  * @param
  * @note
  * @retval
  *****************************************************************************/
  void app_task_status_error_handle( osThreadId_t *thread_id )
  {
    if(*thread_id==defaultTaskHandle)
    {

    }
    else
    {
      //reestart
      osThreadTerminate(*thread_id);
      if(*thread_id==myTask03Handle)
      {
        myTask03Handle = osThreadNew(keyScanTask03, NULL, &myTask03_attributes);
      }
      else if(*thread_id==myTask02Handle)
      {
        IS3_init();
        //myTask02Handle = osThreadNew(auxTask02, NULL, &myTask02_attributes);
      }
      else if(*thread_id==myTask04Handle)
      {
        myTask04Handle = osThreadNew(laserWorkTask04, NULL, &myTask04_attributes);
      }
      else if(*thread_id==myTask05Handle)
      {
        myTask05Handle = osThreadNew(fastAuxTask05, NULL, &myTask05_attributes);
      }
      else if(*thread_id==myTask06Handle)
      {
        myTask06Handle = osThreadNew(hmiAppTask06, NULL, &myTask06_attributes);
      }
      else if(*thread_id==myTask07Handle)
      {
        myTask07Handle = osThreadNew(canReceiveTask07, NULL, &myTask07_attributes);
      }
      else if(*thread_id==myTask08Handle)
      {
        myTask08Handle = osThreadNew(powerOffTask08, NULL, &myTask08_attributes);
      }
      else if(*thread_id==myTask09Handle)
      {
        myTask09Handle = osThreadNew(laserProhotTask09, NULL, &myTask09_attributes);
      }
      else if(*thread_id==myTask10Handle)
      {
        myTask10Handle = osThreadNew(ge2117ManageTask10, NULL, &myTask10_attributes);
      }
      else if(*thread_id==myTask11Handle)
      {
        myTask11Handle = osThreadNew(musicTask11, NULL, &myTask11_attributes);
      }
    }
  }
    /************************************************************************//**
  * @brief 内存使用状态
  * @param
  * @note
  * @retval
  *****************************************************************************/
 void app_sram_status_monitor( void )
 {
  osThreadState_t taskState;
  uint32_t taskSize,taskSpace,sumtaskSize=0,sumtaskSpace=0;
  taskState=osThreadGetState(defaultTaskHandle);
  taskSize= defaultTask_attributes.stack_size ;
  taskSpace=osThreadGetStackSpace(defaultTaskHandle);
  //DEBUG_PRINTF("defaultTask s=%d Size=%d Space=%d \r\n",taskState,taskSize,taskSpace);
  sumtaskSize+=taskSize;
  sumtaskSpace+=taskSpace;
  taskState = osThreadGetState(myTask02Handle);
  taskSize= myTask02_attributes.stack_size ;
  taskSpace=osThreadGetStackSpace(myTask02Handle);
  //DEBUG_PRINTF("myTask02 s=%d Size=%d Space=%d \r\n",taskState,taskSize,taskSpace);
  if(taskState==osThreadError||taskSpace<50)
  {
    if( taskSpace<50) DEBUG_PRINTF(" out of memory2!\r\n");
    app_task_status_error_handle(&myTask02Handle);
  }
  sumtaskSize+=taskSize;
  sumtaskSpace+=taskSpace;
  taskState=osThreadGetState(myTask03Handle);
  taskSize= myTask03_attributes.stack_size ;
  taskSpace=osThreadGetStackSpace(myTask03Handle);
 // DEBUG_PRINTF("myTask03 s=%d Size=%d Space=%d \r\n",taskState,taskSize,taskSpace);
  if(taskState==osThreadError||taskSpace<50)
  {
    if(taskSpace<50) DEBUG_PRINTF(" out of memory3!\r\n");
    app_task_status_error_handle( &myTask02Handle);
  }
  sumtaskSize+=taskSize;
  sumtaskSpace+=taskSpace;
  taskState=osThreadGetState(myTask04Handle);
  taskSize= myTask04_attributes.stack_size ;
  taskSpace=osThreadGetStackSpace(myTask04Handle);
  //DEBUG_PRINTF("myTask04 s=%d Size=%d Space=%d \r\n",taskState,taskSize,taskSpace);
  if(taskState==osThreadError||taskSpace<50)
  {
    if( taskSpace<50) DEBUG_PRINTF(" out of memory4!\r\n");
    app_task_status_error_handle( &myTask03Handle);
  }
  sumtaskSize+=taskSize;
  sumtaskSpace+=taskSpace;
  taskState=osThreadGetState(myTask05Handle);
  taskSize= myTask05_attributes.stack_size ;
  taskSpace=osThreadGetStackSpace(myTask04Handle);
  //DEBUG_PRINTF("myTask05 s=%d Size=%d Space=%d \r\n",taskState,taskSize,taskSpace);
  if(taskState==osThreadError||taskSpace<50)
  {
    if( taskSpace<50) DEBUG_PRINTF(" out of memory5!\r\n");
    app_task_status_error_handle( &myTask05Handle);
  }
  sumtaskSize+=taskSize;
  sumtaskSpace+=taskSpace;
  taskState=osThreadGetState(myTask06Handle);
  taskSize= myTask06_attributes.stack_size ;
  taskSpace=osThreadGetStackSpace(myTask06Handle);
  //DEBUG_PRINTF("myTask06 s=%d Size=%d Space=%d \r\n",taskState,taskSize,taskSpace);
  if(taskState==osThreadError||taskSpace<50)
  {
    if( taskSpace<50) DEBUG_PRINTF(" out of memory6!\r\n");
    app_task_status_error_handle( &myTask06Handle);
  }
  sumtaskSize+=taskSize;
  sumtaskSpace+=taskSpace;
  taskState=osThreadGetState(myTask07Handle);
  taskSize= myTask07_attributes.stack_size ;
  taskSpace=osThreadGetStackSpace(myTask07Handle);
 // DEBUG_PRINTF("myTask07 s=%d Size=%d Space=%d \r\n",taskState,taskSize,taskSpace);
  if(taskState==osThreadError||taskSpace<50)
  {
    if( taskSpace<50) DEBUG_PRINTF(" out of memory7!\r\n");
    app_task_status_error_handle( &myTask07Handle);
  }
  sumtaskSize+=taskSize;
  sumtaskSpace+=taskSpace;
  taskState=osThreadGetState(myTask08Handle);
  taskSize= myTask08_attributes.stack_size;
  taskSpace=osThreadGetStackSpace(myTask08Handle);
 // DEBUG_PRINTF("myTask08 s=%d Size=%d Space=%d \r\n",taskState,taskSize,taskSpace);
  if(taskState==osThreadError||taskSpace<50)
  {
    if( taskSpace<50) DEBUG_PRINTF(" out of memory8!\r\n");
    app_task_status_error_handle( &myTask08Handle);
  }
  sumtaskSize+=taskSize;
  sumtaskSpace+=taskSpace;
  taskState=osThreadGetState(myTask09Handle);
  taskSize= myTask09_attributes.stack_size ;
  taskSpace=osThreadGetStackSpace(myTask09Handle);
 //DEBUG_PRINTF("myTask09 s=%d Size=%d Space=%d \r\n",taskState,taskSize,taskSpace);
  if(taskState==osThreadError||taskSpace<50)
  {
    if( taskSpace<50) DEBUG_PRINTF(" out of memory9!\r\n");
    app_task_status_error_handle( &myTask09Handle);
  }
  sumtaskSize+=taskSize;
  sumtaskSpace+=taskSpace;
  taskState=osThreadGetState(myTask10Handle);
  taskSize= myTask10_attributes.stack_size ;
  taskSpace=osThreadGetStackSpace(myTask10Handle);
  //DEBUG_PRINTF("myTask10 s=%d Size=%d Space=%d \r\n",taskState,taskSize,taskSpace);
  if(taskState==osThreadError||taskSpace<50)
  {
    if( taskSpace<50) DEBUG_PRINTF(" out of memory10!\r\n");
    app_task_status_error_handle( &myTask10Handle);
  }
  sumtaskSize+=taskSize;
  sumtaskSpace+=taskSpace;
  taskState=osThreadGetState(myTask11Handle);
  taskSize= myTask11_attributes.stack_size ;
  taskSpace=osThreadGetStackSpace(myTask11Handle);
  //DEBUG_PRINTF("myTask11 s=%d Size=%d Space=%d \r\n",taskState,taskSize,taskSpace);
  if(taskState==osThreadError||taskSpace<50)
  {
    if( taskSpace<50) DEBUG_PRINTF(" out of memory11!\r\n");
    app_task_status_error_handle( &myTask11Handle);
  }
  sumtaskSize+=taskSize;
  sumtaskSpace+=taskSpace;
  //DEBUG_PRINTF("all cpuAll=%d cpuUse=%d =%d\r\n",sumtaskSize,sumtaskSize-sumtaskSpace,(sumtaskSize-sumtaskSpace)*100/sumtaskSize);

 }
/* USER CODE END Application */
